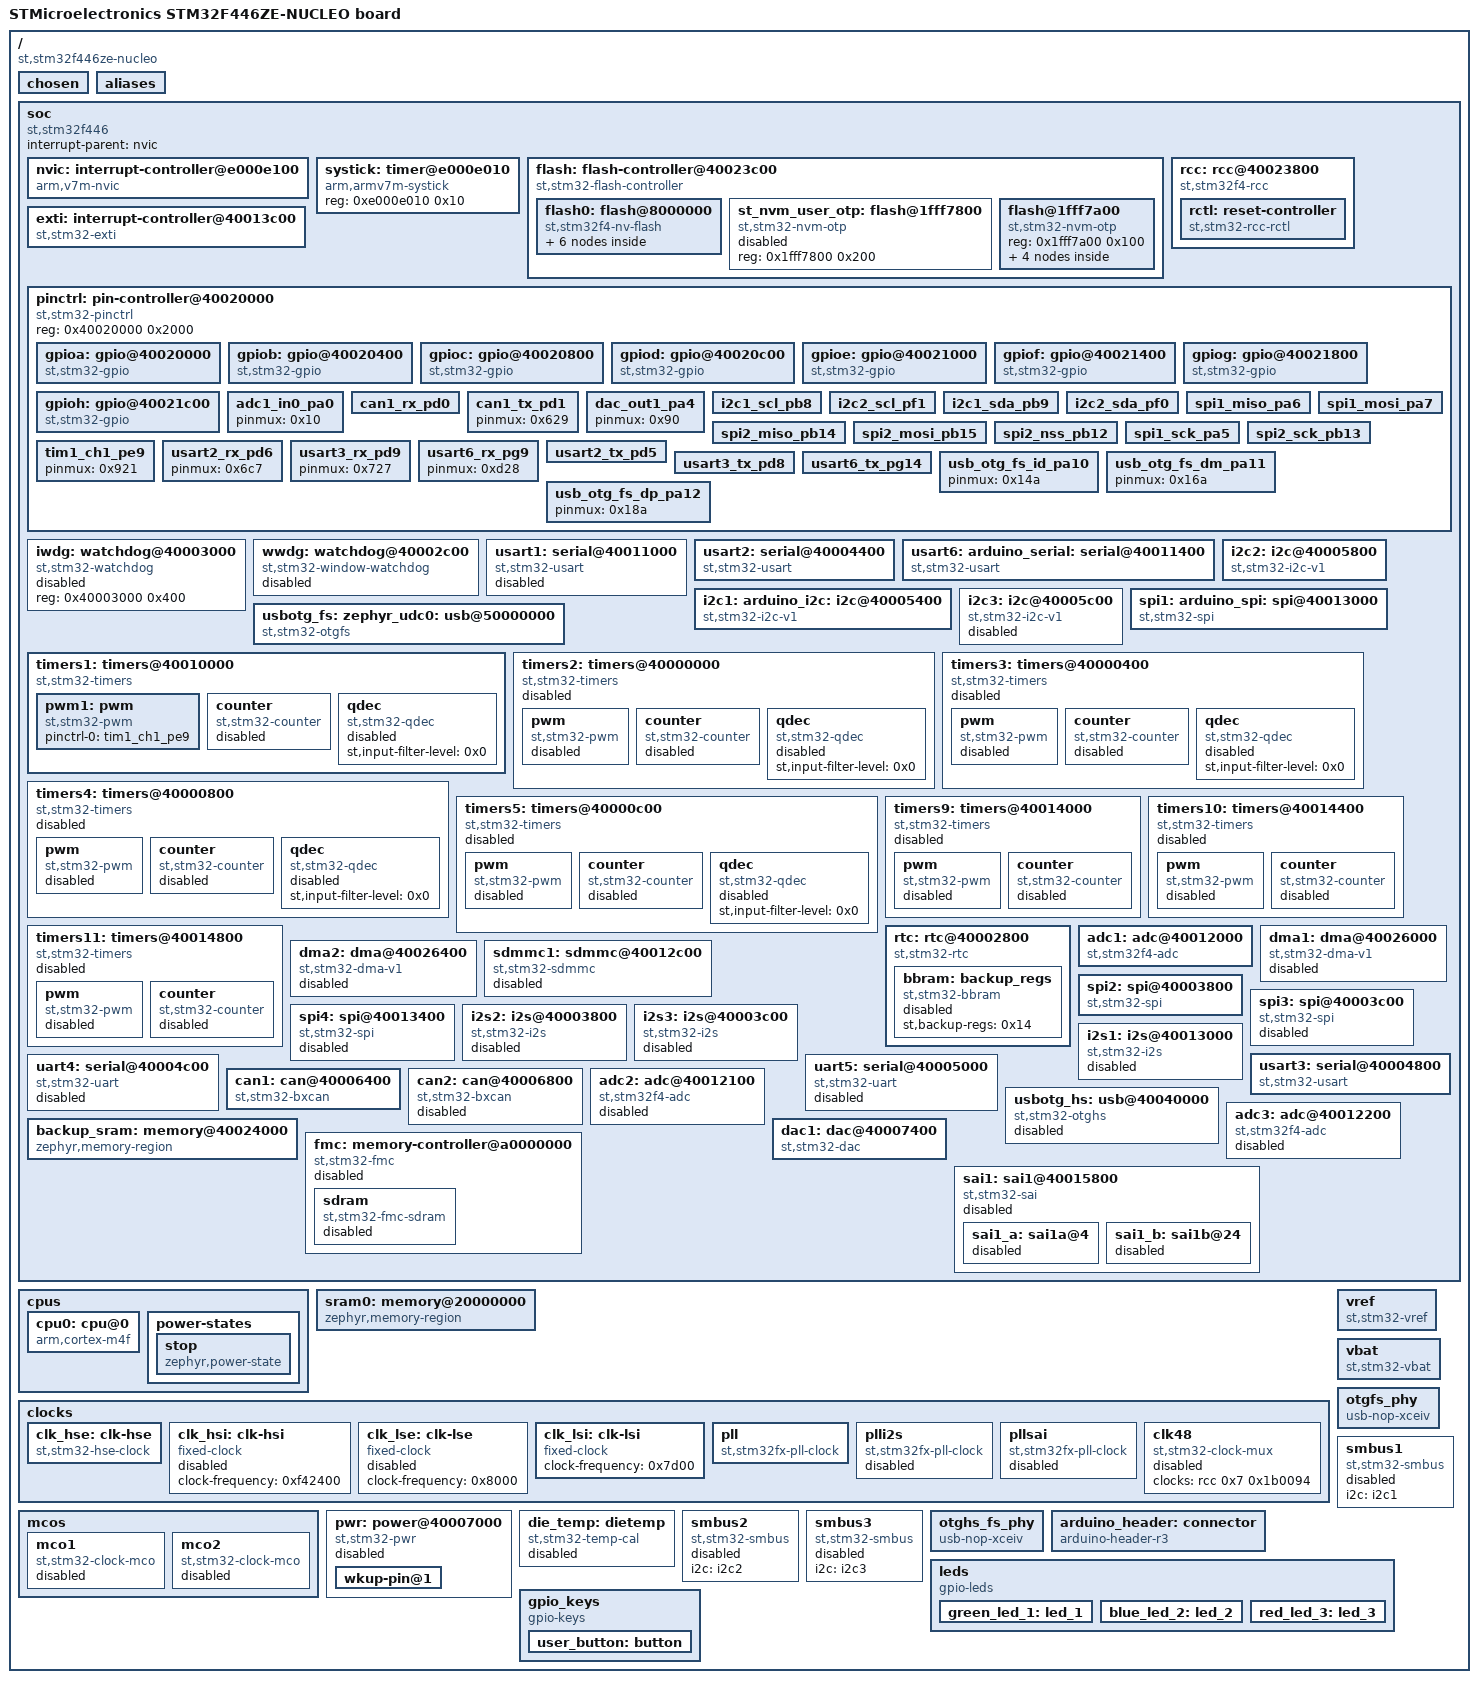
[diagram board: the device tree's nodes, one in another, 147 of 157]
/dts-v1/;

/* node '/' defined in zephyr/dts/common/skeleton.dtsi:9 */
/ {
	#address-cells = < 0x1 >;                              /* in zephyr/dts/common/skeleton.dtsi:10 */
	#size-cells = < 0x1 >;                                 /* in zephyr/dts/common/skeleton.dtsi:11 */
	model = "STMicroelectronics STM32F446ZE-NUCLEO board"; /* in zephyr/boards/st/nucleo_f446ze/nucleo_f446ze.dts:14 */
	compatible = "st,stm32f446ze-nucleo";                  /* in zephyr/boards/st/nucleo_f446ze/nucleo_f446ze.dts:15 */

	/* node '/chosen' defined in zephyr/dts/common/skeleton.dtsi:13 */
	chosen {
		zephyr,flash-controller = &flash;     /* in zephyr/dts/arm/st/f4/stm32f4.dtsi:26 */
		zephyr,system-timer-companion = &rtc; /* in zephyr/dts/arm/st/f4/stm32f4.dtsi:27 */
		zephyr,console = &usart3;             /* in zephyr/boards/st/nucleo_f446ze/nucleo_f446ze.dts:18 */
		zephyr,shell-uart = &usart3;          /* in zephyr/boards/st/nucleo_f446ze/nucleo_f446ze.dts:19 */
		zephyr,sram = &sram0;                 /* in zephyr/boards/st/nucleo_f446ze/nucleo_f446ze.dts:20 */
		zephyr,flash = &flash0;               /* in zephyr/boards/st/nucleo_f446ze/nucleo_f446ze.dts:21 */
		zephyr,canbus = &can1;                /* in zephyr/boards/st/nucleo_f446ze/nucleo_f446ze.dts:22 */
	};

	/* node '/aliases' defined in zephyr/dts/common/skeleton.dtsi:15 */
	aliases {
		led0 = &green_led_1;  /* in zephyr/boards/st/nucleo_f446ze/nucleo_f446ze.dts:55 */
		led1 = &blue_led_2;   /* in zephyr/boards/st/nucleo_f446ze/nucleo_f446ze.dts:56 */
		led2 = &red_led_3;    /* in zephyr/boards/st/nucleo_f446ze/nucleo_f446ze.dts:57 */
		sw0 = &user_button;   /* in zephyr/boards/st/nucleo_f446ze/nucleo_f446ze.dts:58 */
		volt-sensor0 = &vref; /* in zephyr/boards/st/nucleo_f446ze/nucleo_f446ze.dts:59 */
		volt-sensor1 = &vbat; /* in zephyr/boards/st/nucleo_f446ze/nucleo_f446ze.dts:60 */
	};

	/* node '/soc' defined in zephyr/dts/arm/armv7-m.dtsi:6 */
	soc {
		#address-cells = < 0x1 >;     /* in zephyr/dts/arm/armv7-m.dtsi:7 */
		#size-cells = < 0x1 >;        /* in zephyr/dts/arm/armv7-m.dtsi:8 */
		interrupt-parent = < &nvic >; /* in zephyr/dts/arm/armv7-m.dtsi:10 */
		ranges;                       /* in zephyr/dts/arm/armv7-m.dtsi:11 */
		compatible = "st,stm32f446",
		             "st,stm32f4",
		             "simple-bus";    /* in zephyr/dts/arm/st/f4/stm32f446.dtsi:29 */

		/* node '/soc/interrupt-controller@e000e100' defined in zephyr/dts/arm/armv7-m.dtsi:13 */
		nvic: interrupt-controller@e000e100 {
			#address-cells = < 0x1 >;            /* in zephyr/dts/arm/armv7-m.dtsi:14 */
			compatible = "arm,v7m-nvic";         /* in zephyr/dts/arm/armv7-m.dtsi:15 */
			reg = < 0xe000e100 0xc00 >;          /* in zephyr/dts/arm/armv7-m.dtsi:16 */
			interrupt-controller;                /* in zephyr/dts/arm/armv7-m.dtsi:17 */
			#interrupt-cells = < 0x2 >;          /* in zephyr/dts/arm/armv7-m.dtsi:18 */
			arm,num-irq-priority-bits = < 0x4 >; /* in zephyr/dts/arm/st/f4/stm32f4.dtsi:729 */
			phandle = < 0x1 >;                   /* in zephyr/dts/arm/armv7-m.dtsi:10 */
		};

		/* node '/soc/timer@e000e010' defined in zephyr/dts/arm/armv7-m.dtsi:21 */
		systick: timer@e000e010 {
			compatible = "arm,armv7m-systick"; /* in zephyr/dts/arm/armv7-m.dtsi:22 */
			reg = < 0xe000e010 0x10 >;         /* in zephyr/dts/arm/armv7-m.dtsi:23 */
		};

		/* node '/soc/flash-controller@40023c00' defined in zephyr/dts/arm/st/f4/stm32f4.dtsi:112 */
		flash: flash-controller@40023c00 {
			compatible = "st,stm32-flash-controller",
			             "st,stm32f4-flash-controller"; /* in zephyr/dts/arm/st/f4/stm32f4.dtsi:113 */
			reg = < 0x40023c00 0x400 >;                 /* in zephyr/dts/arm/st/f4/stm32f4.dtsi:114 */
			interrupts = < 0x4 0x0 >;                   /* in zephyr/dts/arm/st/f4/stm32f4.dtsi:115 */
			#address-cells = < 0x1 >;                   /* in zephyr/dts/arm/st/f4/stm32f4.dtsi:117 */
			#size-cells = < 0x1 >;                      /* in zephyr/dts/arm/st/f4/stm32f4.dtsi:118 */
			ranges;                                     /* in zephyr/dts/arm/st/f4/stm32f4.dtsi:119 */

			/* node '/soc/flash-controller@40023c00/flash@8000000' defined in zephyr/dts/arm/st/f4/stm32f4.dtsi:121 */
			flash0: flash@8000000 {
				compatible = "st,stm32f4-nv-flash",
				             "st,stm32-nv-flash",
				             "soc-nv-flash";        /* in zephyr/dts/arm/st/f4/stm32f4.dtsi:122 */
				#address-cells = < 0x1 >;           /* in zephyr/dts/arm/st/f4/stm32f4.dtsi:124 */
				#size-cells = < 0x1 >;              /* in zephyr/dts/arm/st/f4/stm32f4.dtsi:125 */
				write-block-size = < 0x1 >;         /* in zephyr/dts/arm/st/f4/stm32f4.dtsi:126 */
				max-erase-time = < 0xfa0 >;         /* in zephyr/dts/arm/st/f4/stm32f4.dtsi:128 */
				reg = < 0x8000000 0x80000 >;        /* in zephyr/dts/arm/st/f4/stm32f446Xe.dtsi:17 */
				ranges = < 0x0 0x8000000 0x80000 >; /* in zephyr/dts/arm/st/f4/stm32f446Xe.dtsi:18 */

				/* node '/soc/flash-controller@40023c00/flash@8000000/partitions' defined in zephyr/boards/st/nucleo_f446ze/nucleo_f446ze.dts:188 */
				partitions {
					#address-cells = < 0x1 >; /* in zephyr/boards/st/nucleo_f446ze/nucleo_f446ze.dts:189 */
					#size-cells = < 0x1 >;    /* in zephyr/boards/st/nucleo_f446ze/nucleo_f446ze.dts:190 */
					ranges;                   /* in zephyr/boards/st/nucleo_f446ze/nucleo_f446ze.dts:191 */

					/* node '/soc/flash-controller@40023c00/flash@8000000/partitions/partition@0' defined in zephyr/boards/st/nucleo_f446ze/nucleo_f446ze.dts:193 */
					boot_partition: partition@0 {
						compatible = "zephyr,mapped-partition"; /* in zephyr/boards/st/nucleo_f446ze/nucleo_f446ze.dts:194 */
						label = "mcuboot";                      /* in zephyr/boards/st/nucleo_f446ze/nucleo_f446ze.dts:195 */
						reg = < 0x0 0x10000 >;                  /* in zephyr/boards/st/nucleo_f446ze/nucleo_f446ze.dts:196 */
						read-only;                              /* in zephyr/boards/st/nucleo_f446ze/nucleo_f446ze.dts:197 */
					};

					/* node '/soc/flash-controller@40023c00/flash@8000000/partitions/partition@10000' defined in zephyr/boards/st/nucleo_f446ze/nucleo_f446ze.dts:205 */
					storage_partition: partition@10000 {
						compatible = "zephyr,mapped-partition"; /* in zephyr/boards/st/nucleo_f446ze/nucleo_f446ze.dts:206 */
						label = "storage";                      /* in zephyr/boards/st/nucleo_f446ze/nucleo_f446ze.dts:207 */
						reg = < 0x10000 0x10000 >;              /* in zephyr/boards/st/nucleo_f446ze/nucleo_f446ze.dts:208 */
					};

					/* node '/soc/flash-controller@40023c00/flash@8000000/partitions/partition@20000' defined in zephyr/boards/st/nucleo_f446ze/nucleo_f446ze.dts:211 */
					slot0_partition: partition@20000 {
						compatible = "zephyr,mapped-partition"; /* in zephyr/boards/st/nucleo_f446ze/nucleo_f446ze.dts:212 */
						label = "image-0";                      /* in zephyr/boards/st/nucleo_f446ze/nucleo_f446ze.dts:213 */
						reg = < 0x20000 0x20000 >;              /* in zephyr/boards/st/nucleo_f446ze/nucleo_f446ze.dts:214 */
					};

					/* node '/soc/flash-controller@40023c00/flash@8000000/partitions/partition@40000' defined in zephyr/boards/st/nucleo_f446ze/nucleo_f446ze.dts:217 */
					slot1_partition: partition@40000 {
						compatible = "zephyr,mapped-partition"; /* in zephyr/boards/st/nucleo_f446ze/nucleo_f446ze.dts:218 */
						label = "image-1";                      /* in zephyr/boards/st/nucleo_f446ze/nucleo_f446ze.dts:219 */
						reg = < 0x40000 0x20000 >;              /* in zephyr/boards/st/nucleo_f446ze/nucleo_f446ze.dts:220 */
					};

					/* node '/soc/flash-controller@40023c00/flash@8000000/partitions/partition@60000' defined in zephyr/boards/st/nucleo_f446ze/nucleo_f446ze.dts:223 */
					scratch_partition: partition@60000 {
						compatible = "zephyr,mapped-partition"; /* in zephyr/boards/st/nucleo_f446ze/nucleo_f446ze.dts:224 */
						label = "image-scratch";                /* in zephyr/boards/st/nucleo_f446ze/nucleo_f446ze.dts:225 */
						reg = < 0x60000 0x20000 >;              /* in zephyr/boards/st/nucleo_f446ze/nucleo_f446ze.dts:226 */
					};
				};
			};

			/* node '/soc/flash-controller@40023c00/flash@1fff7800' defined in zephyr/dts/arm/st/f4/stm32f4.dtsi:131 */
			st_nvm_user_otp: flash@1fff7800 {
				compatible = "st,stm32-nvm-otp"; /* in zephyr/dts/arm/st/f4/stm32f4.dtsi:132 */
				reg = < 0x1fff7800 0x200 >;      /* in zephyr/dts/arm/st/f4/stm32f4.dtsi:133 */
				status = "disabled";             /* in zephyr/dts/arm/st/f4/stm32f4.dtsi:134 */
			};

			/* node '/soc/flash-controller@40023c00/flash@1fff7a00' defined in zephyr/dts/arm/st/f4/stm32f4.dtsi:148 */
			flash@1fff7a00 {
				compatible = "st,stm32-nvm-otp"; /* in zephyr/dts/arm/st/f4/stm32f4.dtsi:149 */
				reg = < 0x1fff7a00 0x100 >;      /* in zephyr/dts/arm/st/f4/stm32f4.dtsi:150 */

				/* node '/soc/flash-controller@40023c00/flash@1fff7a00/nvmem-layout' defined in zephyr/dts/arm/st/f4/stm32f4.dtsi:152 */
				nvmem-layout {
					compatible = "fixed-layout"; /* in zephyr/dts/arm/st/f4/stm32f4.dtsi:153 */
					#address-cells = < 0x1 >;    /* in zephyr/dts/arm/st/f4/stm32f4.dtsi:154 */
					#size-cells = < 0x1 >;       /* in zephyr/dts/arm/st/f4/stm32f4.dtsi:155 */

					/* node '/soc/flash-controller@40023c00/flash@1fff7a00/nvmem-layout/vrefint@2a' defined in zephyr/dts/arm/st/f4/stm32f4.dtsi:157 */
					vrefint_otp: vrefint@2a {
						reg = < 0x2a 0x2 >;          /* in zephyr/dts/arm/st/f4/stm32f4.dtsi:158 */
						#nvmem-cell-cells = < 0x0 >; /* in zephyr/dts/arm/st/f4/stm32f4.dtsi:159 */
						read-only;                   /* in zephyr/dts/arm/st/f4/stm32f4.dtsi:160 */
						phandle = < 0x29 >;          /* in zephyr/dts/arm/st/f4/stm32f4.dtsi:685 */
					};

					/* node '/soc/flash-controller@40023c00/flash@1fff7a00/nvmem-layout/ts-cal1@2c' defined in zephyr/dts/arm/st/f4/stm32f4.dtsi:163 */
					ts_cal1_otp: ts-cal1@2c {
						reg = < 0x2c 0x2 >;          /* in zephyr/dts/arm/st/f4/stm32f4.dtsi:164 */
						#nvmem-cell-cells = < 0x0 >; /* in zephyr/dts/arm/st/f4/stm32f4.dtsi:165 */
						read-only;                   /* in zephyr/dts/arm/st/f4/stm32f4.dtsi:166 */
						phandle = < 0x26 >;          /* in zephyr/dts/arm/st/f4/stm32f4.dtsi:674 */
					};

					/* node '/soc/flash-controller@40023c00/flash@1fff7a00/nvmem-layout/ts-cal2@2e' defined in zephyr/dts/arm/st/f4/stm32f4.dtsi:169 */
					ts_cal2_otp: ts-cal2@2e {
						reg = < 0x2e 0x2 >;          /* in zephyr/dts/arm/st/f4/stm32f4.dtsi:170 */
						#nvmem-cell-cells = < 0x0 >; /* in zephyr/dts/arm/st/f4/stm32f4.dtsi:171 */
						read-only;                   /* in zephyr/dts/arm/st/f4/stm32f4.dtsi:172 */
						phandle = < 0x27 >;          /* in zephyr/dts/arm/st/f4/stm32f4.dtsi:674 */
					};
				};
			};
		};

		/* node '/soc/rcc@40023800' defined in zephyr/dts/arm/st/f4/stm32f4.dtsi:178 */
		rcc: rcc@40023800 {
			compatible = "st,stm32f4-rcc";   /* in zephyr/dts/arm/st/f4/stm32f4.dtsi:179 */
			#clock-cells = < 0x2 >;          /* in zephyr/dts/arm/st/f4/stm32f4.dtsi:180 */
			reg = < 0x40023800 0x400 >;      /* in zephyr/dts/arm/st/f4/stm32f4.dtsi:181 */
			clocks = < &pll >;               /* in zephyr/boards/st/nucleo_f446ze/nucleo_f446ze.dts:84 */
			clock-frequency = < 0xa037a00 >; /* in zephyr/boards/st/nucleo_f446ze/nucleo_f446ze.dts:85 */
			ahb-prescaler = < 0x1 >;         /* in zephyr/boards/st/nucleo_f446ze/nucleo_f446ze.dts:86 */
			apb1-prescaler = < 0x4 >;        /* in zephyr/boards/st/nucleo_f446ze/nucleo_f446ze.dts:87 */
			apb2-prescaler = < 0x2 >;        /* in zephyr/boards/st/nucleo_f446ze/nucleo_f446ze.dts:88 */
			phandle = < 0x3 >;               /* in zephyr/dts/arm/st/f4/stm32f4.dtsi:195 */

			/* node '/soc/rcc@40023800/reset-controller' defined in zephyr/dts/arm/st/f4/stm32f4.dtsi:183 */
			rctl: reset-controller {
				compatible = "st,stm32-rcc-rctl"; /* in zephyr/dts/arm/st/f4/stm32f4.dtsi:184 */
				#reset-cells = < 0x1 >;           /* in zephyr/dts/arm/st/f4/stm32f4.dtsi:185 */
				phandle = < 0x4 >;                /* in zephyr/dts/arm/st/f4/stm32f4.dtsi:294 */
			};
		};

		/* node '/soc/interrupt-controller@40013c00' defined in zephyr/dts/arm/st/f4/stm32f4.dtsi:189 */
		exti: interrupt-controller@40013c00 {
			compatible = "st,stm32-exti";  /* in zephyr/dts/arm/st/f4/stm32f4.dtsi:190 */
			interrupt-controller;          /* in zephyr/dts/arm/st/f4/stm32f4.dtsi:191 */
			#interrupt-cells = < 0x1 >;    /* in zephyr/dts/arm/st/f4/stm32f4.dtsi:192 */
			#address-cells = < 0x0 >;      /* in zephyr/dts/arm/st/f4/stm32f4.dtsi:193 */
			reg = < 0x40013c00 0x400 >;    /* in zephyr/dts/arm/st/f4/stm32f4.dtsi:194 */
			clocks = < &rcc 0x44 0x4000 >; /* in zephyr/dts/arm/st/f4/stm32f4.dtsi:195 */
			num-lines = < 0x20 >;          /* in zephyr/dts/arm/st/f4/stm32f4.dtsi:196 */
			interrupts = < 0x6 0x0 >,
			             < 0x7 0x0 >,
			             < 0x8 0x0 >,
			             < 0x9 0x0 >,
			             < 0xa 0x0 >,
			             < 0x17 0x0 >,
			             < 0x28 0x0 >;     /* in zephyr/dts/arm/st/f4/stm32f4.dtsi:197 */
			interrupt-names = "line0",
			                  "line1",
			                  "line2",
			                  "line3",
			                  "line4",
			                  "line5-9",
			                  "line10-15"; /* in zephyr/dts/arm/st/f4/stm32f4.dtsi:199 */
			line-ranges = < 0x0 0x1 >,
			              < 0x1 0x1 >,
			              < 0x2 0x1 >,
			              < 0x3 0x1 >,
			              < 0x4 0x1 >,
			              < 0x5 0x5 >,
			              < 0xa 0x6 >;     /* in zephyr/dts/arm/st/f4/stm32f4.dtsi:201 */
		};

		/* node '/soc/pin-controller@40020000' defined in zephyr/dts/arm/st/f4/stm32f4.dtsi:205 */
		pinctrl: pin-controller@40020000 {
			compatible = "st,stm32-pinctrl"; /* in zephyr/dts/arm/st/f4/stm32f4.dtsi:206 */
			#address-cells = < 0x1 >;        /* in zephyr/dts/arm/st/f4/stm32f4.dtsi:207 */
			#size-cells = < 0x1 >;           /* in zephyr/dts/arm/st/f4/stm32f4.dtsi:208 */
			reg = < 0x40020000 0x2000 >;     /* in zephyr/dts/arm/st/f4/stm32f4.dtsi:209 */

			/* node '/soc/pin-controller@40020000/gpio@40020000' defined in zephyr/dts/arm/st/f4/stm32f4.dtsi:211 */
			gpioa: gpio@40020000 {
				compatible = "st,stm32-gpio"; /* in zephyr/dts/arm/st/f4/stm32f4.dtsi:212 */
				gpio-controller;              /* in zephyr/dts/arm/st/f4/stm32f4.dtsi:213 */
				#gpio-cells = < 0x2 >;        /* in zephyr/dts/arm/st/f4/stm32f4.dtsi:214 */
				reg = < 0x40020000 0x400 >;   /* in zephyr/dts/arm/st/f4/stm32f4.dtsi:215 */
				clocks = < &rcc 0x30 0x1 >;   /* in zephyr/dts/arm/st/f4/stm32f4.dtsi:216 */
				phandle = < 0x25 >;           /* in zephyr/dts/arm/st/f4/stm32f4.dtsi:668 */
			};

			/* node '/soc/pin-controller@40020000/gpio@40020400' defined in zephyr/dts/arm/st/f4/stm32f4.dtsi:219 */
			gpiob: gpio@40020400 {
				compatible = "st,stm32-gpio"; /* in zephyr/dts/arm/st/f4/stm32f4.dtsi:220 */
				gpio-controller;              /* in zephyr/dts/arm/st/f4/stm32f4.dtsi:221 */
				#gpio-cells = < 0x2 >;        /* in zephyr/dts/arm/st/f4/stm32f4.dtsi:222 */
				reg = < 0x40020400 0x400 >;   /* in zephyr/dts/arm/st/f4/stm32f4.dtsi:223 */
				clocks = < &rcc 0x30 0x2 >;   /* in zephyr/dts/arm/st/f4/stm32f4.dtsi:224 */
				phandle = < 0x31 >;           /* in zephyr/boards/st/nucleo_f446ze/arduino_r3_connector.dtsi:15 */
			};

			/* node '/soc/pin-controller@40020000/gpio@40020800' defined in zephyr/dts/arm/st/f4/stm32f4.dtsi:227 */
			gpioc: gpio@40020800 {
				compatible = "st,stm32-gpio"; /* in zephyr/dts/arm/st/f4/stm32f4.dtsi:228 */
				gpio-controller;              /* in zephyr/dts/arm/st/f4/stm32f4.dtsi:229 */
				#gpio-cells = < 0x2 >;        /* in zephyr/dts/arm/st/f4/stm32f4.dtsi:230 */
				reg = < 0x40020800 0x400 >;   /* in zephyr/dts/arm/st/f4/stm32f4.dtsi:231 */
				clocks = < &rcc 0x30 0x4 >;   /* in zephyr/dts/arm/st/f4/stm32f4.dtsi:232 */
				phandle = < 0x2d >;           /* in zephyr/boards/st/nucleo_f446ze/arduino_r3_connector.dtsi:15 */
			};

			/* node '/soc/pin-controller@40020000/gpio@40020c00' defined in zephyr/dts/arm/st/f4/stm32f4.dtsi:235 */
			gpiod: gpio@40020c00 {
				compatible = "st,stm32-gpio"; /* in zephyr/dts/arm/st/f4/stm32f4.dtsi:236 */
				gpio-controller;              /* in zephyr/dts/arm/st/f4/stm32f4.dtsi:237 */
				#gpio-cells = < 0x2 >;        /* in zephyr/dts/arm/st/f4/stm32f4.dtsi:238 */
				reg = < 0x40020c00 0x400 >;   /* in zephyr/dts/arm/st/f4/stm32f4.dtsi:239 */
				clocks = < &rcc 0x30 0x8 >;   /* in zephyr/dts/arm/st/f4/stm32f4.dtsi:240 */
				phandle = < 0x10 >;           /* in zephyr/boards/st/nucleo_f446ze/nucleo_f446ze.dts:143 */
			};

			/* node '/soc/pin-controller@40020000/gpio@40021000' defined in zephyr/dts/arm/st/f4/stm32f4.dtsi:243 */
			gpioe: gpio@40021000 {
				compatible = "st,stm32-gpio"; /* in zephyr/dts/arm/st/f4/stm32f4.dtsi:244 */
				gpio-controller;              /* in zephyr/dts/arm/st/f4/stm32f4.dtsi:245 */
				#gpio-cells = < 0x2 >;        /* in zephyr/dts/arm/st/f4/stm32f4.dtsi:246 */
				reg = < 0x40021000 0x400 >;   /* in zephyr/dts/arm/st/f4/stm32f4.dtsi:247 */
				clocks = < &rcc 0x30 0x10 >;  /* in zephyr/dts/arm/st/f4/stm32f4.dtsi:248 */
				phandle = < 0x30 >;           /* in zephyr/boards/st/nucleo_f446ze/arduino_r3_connector.dtsi:15 */
			};

			/* node '/soc/pin-controller@40020000/gpio@40021400' defined in zephyr/dts/arm/st/f4/stm32f4.dtsi:251 */
			gpiof: gpio@40021400 {
				compatible = "st,stm32-gpio"; /* in zephyr/dts/arm/st/f4/stm32f4.dtsi:252 */
				gpio-controller;              /* in zephyr/dts/arm/st/f4/stm32f4.dtsi:253 */
				#gpio-cells = < 0x2 >;        /* in zephyr/dts/arm/st/f4/stm32f4.dtsi:254 */
				reg = < 0x40021400 0x400 >;   /* in zephyr/dts/arm/st/f4/stm32f4.dtsi:255 */
				clocks = < &rcc 0x30 0x20 >;  /* in zephyr/dts/arm/st/f4/stm32f4.dtsi:256 */
				phandle = < 0x2e >;           /* in zephyr/boards/st/nucleo_f446ze/arduino_r3_connector.dtsi:15 */
			};

			/* node '/soc/pin-controller@40020000/gpio@40021800' defined in zephyr/dts/arm/st/f4/stm32f4.dtsi:259 */
			gpiog: gpio@40021800 {
				compatible = "st,stm32-gpio"; /* in zephyr/dts/arm/st/f4/stm32f4.dtsi:260 */
				gpio-controller;              /* in zephyr/dts/arm/st/f4/stm32f4.dtsi:261 */
				#gpio-cells = < 0x2 >;        /* in zephyr/dts/arm/st/f4/stm32f4.dtsi:262 */
				reg = < 0x40021800 0x400 >;   /* in zephyr/dts/arm/st/f4/stm32f4.dtsi:263 */
				clocks = < &rcc 0x30 0x40 >;  /* in zephyr/dts/arm/st/f4/stm32f4.dtsi:264 */
				phandle = < 0x2f >;           /* in zephyr/boards/st/nucleo_f446ze/arduino_r3_connector.dtsi:15 */
			};

			/* node '/soc/pin-controller@40020000/gpio@40021c00' defined in zephyr/dts/arm/st/f4/stm32f4.dtsi:267 */
			gpioh: gpio@40021c00 {
				compatible = "st,stm32-gpio"; /* in zephyr/dts/arm/st/f4/stm32f4.dtsi:268 */
				gpio-controller;              /* in zephyr/dts/arm/st/f4/stm32f4.dtsi:269 */
				#gpio-cells = < 0x2 >;        /* in zephyr/dts/arm/st/f4/stm32f4.dtsi:270 */
				reg = < 0x40021c00 0x400 >;   /* in zephyr/dts/arm/st/f4/stm32f4.dtsi:271 */
				clocks = < &rcc 0x30 0x80 >;  /* in zephyr/dts/arm/st/f4/stm32f4.dtsi:272 */
			};

			/* node '/soc/pin-controller@40020000/adc1_in0_pa0' defined in modules/hal/stm32/dts/st/f4/stm32f446z(c-e)tx-pinctrl.dtsi:13 */
			adc1_in0_pa0: adc1_in0_pa0 {
				pinmux = < 0x10 >;  /* in modules/hal/stm32/dts/st/f4/stm32f446z(c-e)tx-pinctrl.dtsi:14 */
				phandle = < 0x16 >; /* in zephyr/boards/st/nucleo_f446ze/nucleo_f446ze.dts:92 */
			};

			/* node '/soc/pin-controller@40020000/can1_rx_pd0' defined in modules/hal/stm32/dts/st/f4/stm32f446z(c-e)tx-pinctrl.dtsi:675 */
			can1_rx_pd0: can1_rx_pd0 {
				pinmux = < 0x609 >; /* in modules/hal/stm32/dts/st/f4/stm32f446z(c-e)tx-pinctrl.dtsi:676 */
				bias-pull-up;       /* in modules/hal/stm32/dts/st/f4/stm32f446z(c-e)tx-pinctrl.dtsi:677 */
				phandle = < 0x1f >; /* in zephyr/boards/st/nucleo_f446ze/nucleo_f446ze.dts:182 */
			};

			/* node '/soc/pin-controller@40020000/can1_tx_pd1' defined in modules/hal/stm32/dts/st/f4/stm32f446z(c-e)tx-pinctrl.dtsi:700 */
			can1_tx_pd1: can1_tx_pd1 {
				pinmux = < 0x629 >; /* in modules/hal/stm32/dts/st/f4/stm32f446z(c-e)tx-pinctrl.dtsi:701 */
				phandle = < 0x20 >; /* in zephyr/boards/st/nucleo_f446ze/nucleo_f446ze.dts:182 */
			};

			/* node '/soc/pin-controller@40020000/dac_out1_pa4' defined in modules/hal/stm32/dts/st/f4/stm32f446z(c-e)tx-pinctrl.dtsi:714 */
			dac_out1_pa4: dac_out1_pa4 {
				pinmux = < 0x90 >;  /* in modules/hal/stm32/dts/st/f4/stm32f446z(c-e)tx-pinctrl.dtsi:715 */
				phandle = < 0x22 >; /* in zephyr/boards/st/nucleo_f446ze/nucleo_f446ze.dts:101 */
			};

			/* node '/soc/pin-controller@40020000/i2c1_scl_pb8' defined in modules/hal/stm32/dts/st/f4/stm32f446z(c-e)tx-pinctrl.dtsi:1290 */
			i2c1_scl_pb8: i2c1_scl_pb8 {
				pinmux = < 0x304 >; /* in modules/hal/stm32/dts/st/f4/stm32f446z(c-e)tx-pinctrl.dtsi:1291 */
				bias-pull-up;       /* in modules/hal/stm32/dts/st/f4/stm32f446z(c-e)tx-pinctrl.dtsi:1292 */
				drive-open-drain;   /* in modules/hal/stm32/dts/st/f4/stm32f446z(c-e)tx-pinctrl.dtsi:1293 */
				phandle = < 0x9 >;  /* in zephyr/boards/st/nucleo_f446ze/nucleo_f446ze.dts:127 */
			};

			/* node '/soc/pin-controller@40020000/i2c2_scl_pf1' defined in modules/hal/stm32/dts/st/f4/stm32f446z(c-e)tx-pinctrl.dtsi:1302 */
			i2c2_scl_pf1: i2c2_scl_pf1 {
				pinmux = < 0xa24 >; /* in modules/hal/stm32/dts/st/f4/stm32f446z(c-e)tx-pinctrl.dtsi:1303 */
				bias-pull-up;       /* in modules/hal/stm32/dts/st/f4/stm32f446z(c-e)tx-pinctrl.dtsi:1304 */
				drive-open-drain;   /* in modules/hal/stm32/dts/st/f4/stm32f446z(c-e)tx-pinctrl.dtsi:1305 */
				phandle = < 0xb >;  /* in zephyr/boards/st/nucleo_f446ze/nucleo_f446ze.dts:134 */
			};

			/* node '/soc/pin-controller@40020000/i2c1_sda_pb9' defined in modules/hal/stm32/dts/st/f4/stm32f446z(c-e)tx-pinctrl.dtsi:1322 */
			i2c1_sda_pb9: i2c1_sda_pb9 {
				pinmux = < 0x324 >; /* in modules/hal/stm32/dts/st/f4/stm32f446z(c-e)tx-pinctrl.dtsi:1323 */
				bias-pull-up;       /* in modules/hal/stm32/dts/st/f4/stm32f446z(c-e)tx-pinctrl.dtsi:1324 */
				drive-open-drain;   /* in modules/hal/stm32/dts/st/f4/stm32f446z(c-e)tx-pinctrl.dtsi:1325 */
				phandle = < 0xa >;  /* in zephyr/boards/st/nucleo_f446ze/nucleo_f446ze.dts:127 */
			};

			/* node '/soc/pin-controller@40020000/i2c2_sda_pf0' defined in modules/hal/stm32/dts/st/f4/stm32f446z(c-e)tx-pinctrl.dtsi:1346 */
			i2c2_sda_pf0: i2c2_sda_pf0 {
				pinmux = < 0xa04 >; /* in modules/hal/stm32/dts/st/f4/stm32f446z(c-e)tx-pinctrl.dtsi:1347 */
				bias-pull-up;       /* in modules/hal/stm32/dts/st/f4/stm32f446z(c-e)tx-pinctrl.dtsi:1348 */
				drive-open-drain;   /* in modules/hal/stm32/dts/st/f4/stm32f446z(c-e)tx-pinctrl.dtsi:1349 */
				phandle = < 0xc >;  /* in zephyr/boards/st/nucleo_f446ze/nucleo_f446ze.dts:134 */
			};

			/* node '/soc/pin-controller@40020000/spi1_miso_pa6' defined in modules/hal/stm32/dts/st/f4/stm32f446z(c-e)tx-pinctrl.dtsi:1941 */
			spi1_miso_pa6: spi1_miso_pa6 {
				pinmux = < 0xc5 >;             /* in modules/hal/stm32/dts/st/f4/stm32f446z(c-e)tx-pinctrl.dtsi:1942 */
				bias-pull-down;                /* in modules/hal/stm32/dts/st/f4/stm32f446z(c-e)tx-pinctrl.dtsi:1943 */
				slew-rate = "very-high-speed"; /* in modules/hal/stm32/dts/st/f4/stm32f446z(c-e)tx-pinctrl.dtsi:1944 */
				phandle = < 0xe >;             /* in zephyr/boards/st/nucleo_f446ze/nucleo_f446ze.dts:141 */
			};

			/* node '/soc/pin-controller@40020000/spi2_miso_pb14' defined in modules/hal/stm32/dts/st/f4/stm32f446z(c-e)tx-pinctrl.dtsi:1953 */
			spi2_miso_pb14: spi2_miso_pb14 {
				pinmux = < 0x3c5 >;            /* in modules/hal/stm32/dts/st/f4/stm32f446z(c-e)tx-pinctrl.dtsi:1954 */
				bias-pull-down;                /* in modules/hal/stm32/dts/st/f4/stm32f446z(c-e)tx-pinctrl.dtsi:1955 */
				slew-rate = "very-high-speed"; /* in modules/hal/stm32/dts/st/f4/stm32f446z(c-e)tx-pinctrl.dtsi:1956 */
				phandle = < 0x19 >;            /* in zephyr/boards/st/nucleo_f446ze/nucleo_f446ze.dts:148 */
			};

			/* node '/soc/pin-controller@40020000/spi1_mosi_pa7' defined in modules/hal/stm32/dts/st/f4/stm32f446z(c-e)tx-pinctrl.dtsi:2003 */
			spi1_mosi_pa7: spi1_mosi_pa7 {
				pinmux = < 0xe5 >;             /* in modules/hal/stm32/dts/st/f4/stm32f446z(c-e)tx-pinctrl.dtsi:2004 */
				bias-pull-down;                /* in modules/hal/stm32/dts/st/f4/stm32f446z(c-e)tx-pinctrl.dtsi:2005 */
				slew-rate = "very-high-speed"; /* in modules/hal/stm32/dts/st/f4/stm32f446z(c-e)tx-pinctrl.dtsi:2006 */
				phandle = < 0xf >;             /* in zephyr/boards/st/nucleo_f446ze/nucleo_f446ze.dts:141 */
			};

			/* node '/soc/pin-controller@40020000/spi2_mosi_pb15' defined in modules/hal/stm32/dts/st/f4/stm32f446z(c-e)tx-pinctrl.dtsi:2015 */
			spi2_mosi_pb15: spi2_mosi_pb15 {
				pinmux = < 0x3e5 >;            /* in modules/hal/stm32/dts/st/f4/stm32f446z(c-e)tx-pinctrl.dtsi:2016 */
				bias-pull-down;                /* in modules/hal/stm32/dts/st/f4/stm32f446z(c-e)tx-pinctrl.dtsi:2017 */
				slew-rate = "very-high-speed"; /* in modules/hal/stm32/dts/st/f4/stm32f446z(c-e)tx-pinctrl.dtsi:2018 */
				phandle = < 0x1a >;            /* in zephyr/boards/st/nucleo_f446ze/nucleo_f446ze.dts:148 */
			};

			/* node '/soc/pin-controller@40020000/spi2_nss_pb12' defined in modules/hal/stm32/dts/st/f4/stm32f446z(c-e)tx-pinctrl.dtsi:2119 */
			spi2_nss_pb12: spi2_nss_pb12 {
				pinmux = < 0x385 >;            /* in modules/hal/stm32/dts/st/f4/stm32f446z(c-e)tx-pinctrl.dtsi:2120 */
				bias-pull-up;                  /* in modules/hal/stm32/dts/st/f4/stm32f446z(c-e)tx-pinctrl.dtsi:2121 */
				slew-rate = "very-high-speed"; /* in modules/hal/stm32/dts/st/f4/stm32f446z(c-e)tx-pinctrl.dtsi:2122 */
				phandle = < 0x17 >;            /* in zephyr/boards/st/nucleo_f446ze/nucleo_f446ze.dts:148 */
			};

			/* node '/soc/pin-controller@40020000/spi1_sck_pa5' defined in modules/hal/stm32/dts/st/f4/stm32f446z(c-e)tx-pinctrl.dtsi:2163 */
			spi1_sck_pa5: spi1_sck_pa5 {
				pinmux = < 0xa5 >;             /* in modules/hal/stm32/dts/st/f4/stm32f446z(c-e)tx-pinctrl.dtsi:2164 */
				bias-pull-down;                /* in modules/hal/stm32/dts/st/f4/stm32f446z(c-e)tx-pinctrl.dtsi:2165 */
				slew-rate = "very-high-speed"; /* in modules/hal/stm32/dts/st/f4/stm32f446z(c-e)tx-pinctrl.dtsi:2166 */
				phandle = < 0xd >;             /* in zephyr/boards/st/nucleo_f446ze/nucleo_f446ze.dts:141 */
			};

			/* node '/soc/pin-controller@40020000/spi2_sck_pb13' defined in modules/hal/stm32/dts/st/f4/stm32f446z(c-e)tx-pinctrl.dtsi:2187 */
			spi2_sck_pb13: spi2_sck_pb13 {
				pinmux = < 0x3a5 >;            /* in modules/hal/stm32/dts/st/f4/stm32f446z(c-e)tx-pinctrl.dtsi:2188 */
				bias-pull-down;                /* in modules/hal/stm32/dts/st/f4/stm32f446z(c-e)tx-pinctrl.dtsi:2189 */
				slew-rate = "very-high-speed"; /* in modules/hal/stm32/dts/st/f4/stm32f446z(c-e)tx-pinctrl.dtsi:2190 */
				phandle = < 0x18 >;            /* in zephyr/boards/st/nucleo_f446ze/nucleo_f446ze.dts:148 */
			};

			/* node '/soc/pin-controller@40020000/tim1_ch1_pe9' defined in modules/hal/stm32/dts/st/f4/stm32f446z(c-e)tx-pinctrl.dtsi:2311 */
			tim1_ch1_pe9: tim1_ch1_pe9 {
				pinmux = < 0x921 >; /* in modules/hal/stm32/dts/st/f4/stm32f446z(c-e)tx-pinctrl.dtsi:2312 */
				phandle = < 0x15 >; /* in zephyr/boards/st/nucleo_f446ze/nucleo_f446ze.dts:166 */
			};

			/* node '/soc/pin-controller@40020000/usart2_rx_pd6' defined in modules/hal/stm32/dts/st/f4/stm32f446z(c-e)tx-pinctrl.dtsi:2663 */
			usart2_rx_pd6: usart2_rx_pd6 {
				pinmux = < 0x6c7 >; /* in modules/hal/stm32/dts/st/f4/stm32f446z(c-e)tx-pinctrl.dtsi:2664 */
				phandle = < 0x6 >;  /* in zephyr/boards/st/nucleo_f446ze/nucleo_f446ze.dts:106 */
			};

			/* node '/soc/pin-controller@40020000/usart3_rx_pd9' defined in modules/hal/stm32/dts/st/f4/stm32f446z(c-e)tx-pinctrl.dtsi:2679 */
			usart3_rx_pd9: usart3_rx_pd9 {
				pinmux = < 0x727 >; /* in modules/hal/stm32/dts/st/f4/stm32f446z(c-e)tx-pinctrl.dtsi:2680 */
				phandle = < 0x1e >; /* in zephyr/boards/st/nucleo_f446ze/nucleo_f446ze.dts:113 */
			};

			/* node '/soc/pin-controller@40020000/usart6_rx_pg9' defined in modules/hal/stm32/dts/st/f4/stm32f446z(c-e)tx-pinctrl.dtsi:2703 */
			usart6_rx_pg9: usart6_rx_pg9 {
				pinmux = < 0xd28 >; /* in modules/hal/stm32/dts/st/f4/stm32f446z(c-e)tx-pinctrl.dtsi:2704 */
				phandle = < 0x8 >;  /* in zephyr/boards/st/nucleo_f446ze/nucleo_f446ze.dts:120 */
			};

			/* node '/soc/pin-controller@40020000/usart2_tx_pd5' defined in modules/hal/stm32/dts/st/f4/stm32f446z(c-e)tx-pinctrl.dtsi:2724 */
			usart2_tx_pd5: usart2_tx_pd5 {
				pinmux = < 0x6a7 >; /* in modules/hal/stm32/dts/st/f4/stm32f446z(c-e)tx-pinctrl.dtsi:2725 */
				bias-pull-up;       /* in modules/hal/stm32/dts/st/f4/stm32f446z(c-e)tx-pinctrl.dtsi:2726 */
				phandle = < 0x5 >;  /* in zephyr/boards/st/nucleo_f446ze/nucleo_f446ze.dts:106 */
			};

			/* node '/soc/pin-controller@40020000/usart3_tx_pd8' defined in modules/hal/stm32/dts/st/f4/stm32f446z(c-e)tx-pinctrl.dtsi:2739 */
			usart3_tx_pd8: usart3_tx_pd8 {
				pinmux = < 0x707 >; /* in modules/hal/stm32/dts/st/f4/stm32f446z(c-e)tx-pinctrl.dtsi:2740 */
				bias-pull-up;       /* in modules/hal/stm32/dts/st/f4/stm32f446z(c-e)tx-pinctrl.dtsi:2741 */
				phandle = < 0x1d >; /* in zephyr/boards/st/nucleo_f446ze/nucleo_f446ze.dts:113 */
			};

			/* node '/soc/pin-controller@40020000/usart6_tx_pg14' defined in modules/hal/stm32/dts/st/f4/stm32f446z(c-e)tx-pinctrl.dtsi:2769 */
			usart6_tx_pg14: usart6_tx_pg14 {
				pinmux = < 0xdc8 >; /* in modules/hal/stm32/dts/st/f4/stm32f446z(c-e)tx-pinctrl.dtsi:2770 */
				bias-pull-up;       /* in modules/hal/stm32/dts/st/f4/stm32f446z(c-e)tx-pinctrl.dtsi:2771 */
				phandle = < 0x7 >;  /* in zephyr/boards/st/nucleo_f446ze/nucleo_f446ze.dts:120 */
			};

			/* node '/soc/pin-controller@40020000/usb_otg_fs_id_pa10' defined in modules/hal/stm32/dts/st/f4/stm32f446z(c-e)tx-pinctrl.dtsi:2784 */
			usb_otg_fs_id_pa10: usb_otg_fs_id_pa10 {
				pinmux = < 0x14a >; /* in modules/hal/stm32/dts/st/f4/stm32f446z(c-e)tx-pinctrl.dtsi:2785 */
				phandle = < 0x14 >; /* in zephyr/boards/st/nucleo_f446ze/nucleo_f446ze.dts:155 */
			};

			/* node '/soc/pin-controller@40020000/usb_otg_fs_dm_pa11' defined in modules/hal/stm32/dts/st/f4/stm32f446z(c-e)tx-pinctrl.dtsi:2788 */
			usb_otg_fs_dm_pa11: usb_otg_fs_dm_pa11 {
				pinmux = < 0x16a >; /* in modules/hal/stm32/dts/st/f4/stm32f446z(c-e)tx-pinctrl.dtsi:2789 */
				phandle = < 0x12 >; /* in zephyr/boards/st/nucleo_f446ze/nucleo_f446ze.dts:155 */
			};

			/* node '/soc/pin-controller@40020000/usb_otg_fs_dp_pa12' defined in modules/hal/stm32/dts/st/f4/stm32f446z(c-e)tx-pinctrl.dtsi:2792 */
			usb_otg_fs_dp_pa12: usb_otg_fs_dp_pa12 {
				pinmux = < 0x18a >; /* in modules/hal/stm32/dts/st/f4/stm32f446z(c-e)tx-pinctrl.dtsi:2793 */
				phandle = < 0x13 >; /* in zephyr/boards/st/nucleo_f446ze/nucleo_f446ze.dts:155 */
			};
		};

		/* node '/soc/watchdog@40003000' defined in zephyr/dts/arm/st/f4/stm32f4.dtsi:276 */
		iwdg: watchdog@40003000 {
			compatible = "st,stm32-watchdog"; /* in zephyr/dts/arm/st/f4/stm32f4.dtsi:277 */
			reg = < 0x40003000 0x400 >;       /* in zephyr/dts/arm/st/f4/stm32f4.dtsi:278 */
			status = "disabled";              /* in zephyr/dts/arm/st/f4/stm32f4.dtsi:279 */
		};

		/* node '/soc/watchdog@40002c00' defined in zephyr/dts/arm/st/f4/stm32f4.dtsi:282 */
		wwdg: watchdog@40002c00 {
			compatible = "st,stm32-window-watchdog"; /* in zephyr/dts/arm/st/f4/stm32f4.dtsi:283 */
			reg = < 0x40002c00 0x400 >;              /* in zephyr/dts/arm/st/f4/stm32f4.dtsi:284 */
			clocks = < &rcc 0x40 0x800 >;            /* in zephyr/dts/arm/st/f4/stm32f4.dtsi:285 */
			interrupts = < 0x0 0x0 >;                /* in zephyr/dts/arm/st/f4/stm32f4.dtsi:286 */
			status = "disabled";                     /* in zephyr/dts/arm/st/f4/stm32f4.dtsi:287 */
		};

		/* node '/soc/serial@40011000' defined in zephyr/dts/arm/st/f4/stm32f4.dtsi:290 */
		usart1: serial@40011000 {
			compatible = "st,stm32-usart",
			             "st,stm32-uart";  /* in zephyr/dts/arm/st/f4/stm32f4.dtsi:291 */
			reg = < 0x40011000 0x400 >;    /* in zephyr/dts/arm/st/f4/stm32f4.dtsi:292 */
			clocks = < &rcc 0x44 0x10 >;   /* in zephyr/dts/arm/st/f4/stm32f4.dtsi:293 */
			resets = < &rctl 0x484 >;      /* in zephyr/dts/arm/st/f4/stm32f4.dtsi:294 */
			interrupts = < 0x25 0x0 >;     /* in zephyr/dts/arm/st/f4/stm32f4.dtsi:295 */
			status = "disabled";           /* in zephyr/dts/arm/st/f4/stm32f4.dtsi:296 */
		};

		/* node '/soc/serial@40004400' defined in zephyr/dts/arm/st/f4/stm32f4.dtsi:299 */
		usart2: serial@40004400 {
			compatible = "st,stm32-usart",
			             "st,stm32-uart";                  /* in zephyr/dts/arm/st/f4/stm32f4.dtsi:300 */
			reg = < 0x40004400 0x400 >;                    /* in zephyr/dts/arm/st/f4/stm32f4.dtsi:301 */
			clocks = < &rcc 0x40 0x20000 >;                /* in zephyr/dts/arm/st/f4/stm32f4.dtsi:302 */
			resets = < &rctl 0x411 >;                      /* in zephyr/dts/arm/st/f4/stm32f4.dtsi:303 */
			interrupts = < 0x26 0x0 >;                     /* in zephyr/dts/arm/st/f4/stm32f4.dtsi:304 */
			pinctrl-0 = < &usart2_tx_pd5 &usart2_rx_pd6 >; /* in zephyr/boards/st/nucleo_f446ze/nucleo_f446ze.dts:106 */
			pinctrl-names = "default";                     /* in zephyr/boards/st/nucleo_f446ze/nucleo_f446ze.dts:107 */
			current-speed = < 0x1c200 >;                   /* in zephyr/boards/st/nucleo_f446ze/nucleo_f446ze.dts:108 */
			status = "okay";                               /* in zephyr/boards/st/nucleo_f446ze/nucleo_f446ze.dts:109 */
		};

		/* node '/soc/serial@40011400' defined in zephyr/dts/arm/st/f4/stm32f4.dtsi:308 */
		usart6: arduino_serial: serial@40011400 {
			compatible = "st,stm32-usart",
			             "st,stm32-uart";                   /* in zephyr/dts/arm/st/f4/stm32f4.dtsi:309 */
			reg = < 0x40011400 0x400 >;                     /* in zephyr/dts/arm/st/f4/stm32f4.dtsi:310 */
			clocks = < &rcc 0x44 0x20 >;                    /* in zephyr/dts/arm/st/f4/stm32f4.dtsi:311 */
			resets = < &rctl 0x485 >;                       /* in zephyr/dts/arm/st/f4/stm32f4.dtsi:312 */
			interrupts = < 0x47 0x0 >;                      /* in zephyr/dts/arm/st/f4/stm32f4.dtsi:313 */
			pinctrl-0 = < &usart6_tx_pg14 &usart6_rx_pg9 >; /* in zephyr/boards/st/nucleo_f446ze/nucleo_f446ze.dts:120 */
			pinctrl-names = "default";                      /* in zephyr/boards/st/nucleo_f446ze/nucleo_f446ze.dts:121 */
			current-speed = < 0x1c200 >;                    /* in zephyr/boards/st/nucleo_f446ze/nucleo_f446ze.dts:122 */
			status = "okay";                                /* in zephyr/boards/st/nucleo_f446ze/nucleo_f446ze.dts:123 */
		};

		/* node '/soc/i2c@40005400' defined in zephyr/dts/arm/st/f4/stm32f4.dtsi:317 */
		i2c1: arduino_i2c: i2c@40005400 {
			compatible = "st,stm32-i2c-v1";              /* in zephyr/dts/arm/st/f4/stm32f4.dtsi:318 */
			#address-cells = < 0x1 >;                    /* in zephyr/dts/arm/st/f4/stm32f4.dtsi:320 */
			#size-cells = < 0x0 >;                       /* in zephyr/dts/arm/st/f4/stm32f4.dtsi:321 */
			reg = < 0x40005400 0x400 >;                  /* in zephyr/dts/arm/st/f4/stm32f4.dtsi:322 */
			clocks = < &rcc 0x40 0x200000 >;             /* in zephyr/dts/arm/st/f4/stm32f4.dtsi:323 */
			interrupts = < 0x1f 0x0 >,
			             < 0x20 0x0 >;                   /* in zephyr/dts/arm/st/f4/stm32f4.dtsi:324 */
			interrupt-names = "event",
			                  "error";                   /* in zephyr/dts/arm/st/f4/stm32f4.dtsi:325 */
			pinctrl-0 = < &i2c1_scl_pb8 &i2c1_sda_pb9 >; /* in zephyr/boards/st/nucleo_f446ze/nucleo_f446ze.dts:127 */
			pinctrl-names = "default";                   /* in zephyr/boards/st/nucleo_f446ze/nucleo_f446ze.dts:128 */
			status = "okay";                             /* in zephyr/boards/st/nucleo_f446ze/nucleo_f446ze.dts:129 */
			clock-frequency = < 0x61a80 >;               /* in zephyr/boards/st/nucleo_f446ze/nucleo_f446ze.dts:130 */
			phandle = < 0x2a >;                          /* in zephyr/dts/arm/st/f4/stm32f4.dtsi:707 */
		};

		/* node '/soc/i2c@40005800' defined in zephyr/dts/arm/st/f4/stm32f4.dtsi:329 */
		i2c2: i2c@40005800 {
			compatible = "st,stm32-i2c-v1";              /* in zephyr/dts/arm/st/f4/stm32f4.dtsi:330 */
			#address-cells = < 0x1 >;                    /* in zephyr/dts/arm/st/f4/stm32f4.dtsi:332 */
			#size-cells = < 0x0 >;                       /* in zephyr/dts/arm/st/f4/stm32f4.dtsi:333 */
			reg = < 0x40005800 0x400 >;                  /* in zephyr/dts/arm/st/f4/stm32f4.dtsi:334 */
			clocks = < &rcc 0x40 0x400000 >;             /* in zephyr/dts/arm/st/f4/stm32f4.dtsi:335 */
			interrupts = < 0x21 0x0 >,
			             < 0x22 0x0 >;                   /* in zephyr/dts/arm/st/f4/stm32f4.dtsi:336 */
			interrupt-names = "event",
			                  "error";                   /* in zephyr/dts/arm/st/f4/stm32f4.dtsi:337 */
			pinctrl-0 = < &i2c2_scl_pf1 &i2c2_sda_pf0 >; /* in zephyr/boards/st/nucleo_f446ze/nucleo_f446ze.dts:134 */
			pinctrl-names = "default";                   /* in zephyr/boards/st/nucleo_f446ze/nucleo_f446ze.dts:135 */
			status = "okay";                             /* in zephyr/boards/st/nucleo_f446ze/nucleo_f446ze.dts:136 */
			clock-frequency = < 0x61a80 >;               /* in zephyr/boards/st/nucleo_f446ze/nucleo_f446ze.dts:137 */
			phandle = < 0x2b >;                          /* in zephyr/dts/arm/st/f4/stm32f4.dtsi:715 */
		};

		/* node '/soc/i2c@40005c00' defined in zephyr/dts/arm/st/f4/stm32f4.dtsi:341 */
		i2c3: i2c@40005c00 {
			compatible = "st,stm32-i2c-v1";  /* in zephyr/dts/arm/st/f4/stm32f4.dtsi:342 */
			clock-frequency = < 0x186a0 >;   /* in zephyr/dts/arm/st/f4/stm32f4.dtsi:343 */
			#address-cells = < 0x1 >;        /* in zephyr/dts/arm/st/f4/stm32f4.dtsi:344 */
			#size-cells = < 0x0 >;           /* in zephyr/dts/arm/st/f4/stm32f4.dtsi:345 */
			reg = < 0x40005c00 0x400 >;      /* in zephyr/dts/arm/st/f4/stm32f4.dtsi:346 */
			clocks = < &rcc 0x40 0x800000 >; /* in zephyr/dts/arm/st/f4/stm32f4.dtsi:347 */
			interrupts = < 0x48 0x0 >,
			             < 0x49 0x0 >;       /* in zephyr/dts/arm/st/f4/stm32f4.dtsi:348 */
			interrupt-names = "event",
			                  "error";       /* in zephyr/dts/arm/st/f4/stm32f4.dtsi:349 */
			status = "disabled";             /* in zephyr/dts/arm/st/f4/stm32f4.dtsi:350 */
			phandle = < 0x2c >;              /* in zephyr/dts/arm/st/f4/stm32f4.dtsi:723 */
		};

		/* node '/soc/spi@40013000' defined in zephyr/dts/arm/st/f4/stm32f4.dtsi:353 */
		spi1: arduino_spi: spi@40013000 {
			compatible = "st,stm32-spi";                                 /* in zephyr/dts/arm/st/f4/stm32f4.dtsi:354 */
			#address-cells = < 0x1 >;                                    /* in zephyr/dts/arm/st/f4/stm32f4.dtsi:355 */
			#size-cells = < 0x0 >;                                       /* in zephyr/dts/arm/st/f4/stm32f4.dtsi:356 */
			reg = < 0x40013000 0x400 >;                                  /* in zephyr/dts/arm/st/f4/stm32f4.dtsi:357 */
			clocks = < &rcc 0x44 0x1000 >;                               /* in zephyr/dts/arm/st/f4/stm32f4.dtsi:358 */
			interrupts = < 0x23 0x0 >;                                   /* in zephyr/dts/arm/st/f4/stm32f4.dtsi:359 */
			st,spi-data-width = "limited-8-16-bit";                      /* in zephyr/dts/arm/st/f4/stm32f4.dtsi:360 */
			pinctrl-0 = < &spi1_sck_pa5 &spi1_miso_pa6 &spi1_mosi_pa7 >; /* in zephyr/boards/st/nucleo_f446ze/nucleo_f446ze.dts:141 */
			pinctrl-names = "default";                                   /* in zephyr/boards/st/nucleo_f446ze/nucleo_f446ze.dts:142 */
			cs-gpios = < &gpiod 0xe 0x11 >;                              /* in zephyr/boards/st/nucleo_f446ze/nucleo_f446ze.dts:143 */
			status = "okay";                                             /* in zephyr/boards/st/nucleo_f446ze/nucleo_f446ze.dts:144 */
		};

		/* node '/soc/usb@50000000' defined in zephyr/dts/arm/st/f4/stm32f4.dtsi:364 */
		usbotg_fs: zephyr_udc0: usb@50000000 {
			compatible = "st,stm32-otgfs";                                               /* in zephyr/dts/arm/st/f4/stm32f4.dtsi:365 */
			reg = < 0x50000000 0x40000 >;                                                /* in zephyr/dts/arm/st/f4/stm32f4.dtsi:366 */
			interrupts = < 0x43 0x0 >;                                                   /* in zephyr/dts/arm/st/f4/stm32f4.dtsi:367 */
			interrupt-names = "otgfs";                                                   /* in zephyr/dts/arm/st/f4/stm32f4.dtsi:368 */
			ram-size = < 0x500 >;                                                        /* in zephyr/dts/arm/st/f4/stm32f4.dtsi:370 */
			maximum-speed = "full-speed";                                                /* in zephyr/dts/arm/st/f4/stm32f4.dtsi:371 */
			phys = < &otgfs_phy >;                                                       /* in zephyr/dts/arm/st/f4/stm32f4.dtsi:372 */
			num-bidir-endpoints = < 0x6 >;                                               /* in zephyr/dts/arm/st/f4/stm32f446.dtsi:92 */
			clocks = < &rcc 0x34 0x80 >,
			         < &rcc 0x7 0x1b0094 >;                                              /* in zephyr/dts/arm/st/f4/stm32f446.dtsi:93 */
			pinctrl-0 = < &usb_otg_fs_dm_pa11 &usb_otg_fs_dp_pa12 &usb_otg_fs_id_pa10 >; /* in zephyr/boards/st/nucleo_f446ze/nucleo_f446ze.dts:155 */
			pinctrl-names = "default";                                                   /* in zephyr/boards/st/nucleo_f446ze/nucleo_f446ze.dts:157 */
			status = "okay";                                                             /* in zephyr/boards/st/nucleo_f446ze/nucleo_f446ze.dts:158 */
		};

		/* node '/soc/timers@40010000' defined in zephyr/dts/arm/st/f4/stm32f4.dtsi:378 */
		timers1: timers@40010000 {
			compatible = "st,stm32-timers"; /* in zephyr/dts/arm/st/f4/stm32f4.dtsi:379 */
			reg = < 0x40010000 0x400 >;     /* in zephyr/dts/arm/st/f4/stm32f4.dtsi:380 */
			clocks = < &rcc 0x44 0x1 >,
			         < &rcc 0x16 0xff >;    /* in zephyr/dts/arm/st/f4/stm32f4.dtsi:381 */
			resets = < &rctl 0x480 >;       /* in zephyr/dts/arm/st/f4/stm32f4.dtsi:383 */
			interrupts = < 0x18 0x0 >,
			             < 0x19 0x0 >,
			             < 0x1a 0x0 >,
			             < 0x1b 0x0 >;      /* in zephyr/dts/arm/st/f4/stm32f4.dtsi:384 */
			interrupt-names = "brk",
			                  "up",
			                  "trgcom",
			                  "cc";         /* in zephyr/dts/arm/st/f4/stm32f4.dtsi:385 */
			st,prescaler = < 0x0 >;         /* in zephyr/dts/arm/st/f4/stm32f4.dtsi:386 */
			status = "okay";                /* in zephyr/boards/st/nucleo_f446ze/nucleo_f446ze.dts:162 */

			/* node '/soc/timers@40010000/pwm' defined in zephyr/dts/arm/st/f4/stm32f4.dtsi:389 */
			pwm1: pwm {
				compatible = "st,stm32-pwm";   /* in zephyr/dts/arm/st/f4/stm32f4.dtsi:390 */
				#pwm-cells = < 0x3 >;          /* in zephyr/dts/arm/st/f4/stm32f4.dtsi:392 */
				status = "okay";               /* in zephyr/boards/st/nucleo_f446ze/nucleo_f446ze.dts:165 */
				pinctrl-0 = < &tim1_ch1_pe9 >; /* in zephyr/boards/st/nucleo_f446ze/nucleo_f446ze.dts:166 */
				pinctrl-names = "default";     /* in zephyr/boards/st/nucleo_f446ze/nucleo_f446ze.dts:167 */
			};

			/* node '/soc/timers@40010000/counter' defined in zephyr/dts/arm/st/f4/stm32f4.dtsi:395 */
			counter {
				compatible = "st,stm32-counter"; /* in zephyr/dts/arm/st/f4/stm32f4.dtsi:396 */
				status = "disabled";             /* in zephyr/dts/arm/st/f4/stm32f4.dtsi:397 */
			};

			/* node '/soc/timers@40010000/qdec' defined in zephyr/dts/arm/st/f4/stm32f4.dtsi:400 */
			qdec {
				compatible = "st,stm32-qdec";    /* in zephyr/dts/arm/st/f4/stm32f4.dtsi:401 */
				st,input-filter-level = < 0x0 >; /* in zephyr/dts/arm/st/f4/stm32f4.dtsi:402 */
				status = "disabled";             /* in zephyr/dts/arm/st/f4/stm32f4.dtsi:403 */
			};
		};

		/* node '/soc/timers@40000000' defined in zephyr/dts/arm/st/f4/stm32f4.dtsi:407 */
		timers2: timers@40000000 {
			compatible = "st,stm32-timers"; /* in zephyr/dts/arm/st/f4/stm32f4.dtsi:408 */
			reg = < 0x40000000 0x400 >;     /* in zephyr/dts/arm/st/f4/stm32f4.dtsi:409 */
			clocks = < &rcc 0x40 0x1 >,
			         < &rcc 0x15 0xff >;    /* in zephyr/dts/arm/st/f4/stm32f4.dtsi:410 */
			resets = < &rctl 0x400 >;       /* in zephyr/dts/arm/st/f4/stm32f4.dtsi:412 */
			interrupts = < 0x1c 0x0 >;      /* in zephyr/dts/arm/st/f4/stm32f4.dtsi:413 */
			interrupt-names = "global";     /* in zephyr/dts/arm/st/f4/stm32f4.dtsi:414 */
			st,prescaler = < 0x0 >;         /* in zephyr/dts/arm/st/f4/stm32f4.dtsi:415 */
			status = "disabled";            /* in zephyr/dts/arm/st/f4/stm32f4.dtsi:416 */

			/* node '/soc/timers@40000000/pwm' defined in zephyr/dts/arm/st/f4/stm32f4.dtsi:418 */
			pwm {
				compatible = "st,stm32-pwm"; /* in zephyr/dts/arm/st/f4/stm32f4.dtsi:419 */
				status = "disabled";         /* in zephyr/dts/arm/st/f4/stm32f4.dtsi:420 */
				#pwm-cells = < 0x3 >;        /* in zephyr/dts/arm/st/f4/stm32f4.dtsi:421 */
			};

			/* node '/soc/timers@40000000/counter' defined in zephyr/dts/arm/st/f4/stm32f4.dtsi:424 */
			counter {
				compatible = "st,stm32-counter"; /* in zephyr/dts/arm/st/f4/stm32f4.dtsi:425 */
				status = "disabled";             /* in zephyr/dts/arm/st/f4/stm32f4.dtsi:426 */
			};

			/* node '/soc/timers@40000000/qdec' defined in zephyr/dts/arm/st/f4/stm32f4.dtsi:429 */
			qdec {
				compatible = "st,stm32-qdec";    /* in zephyr/dts/arm/st/f4/stm32f4.dtsi:430 */
				st,input-filter-level = < 0x0 >; /* in zephyr/dts/arm/st/f4/stm32f4.dtsi:431 */
				status = "disabled";             /* in zephyr/dts/arm/st/f4/stm32f4.dtsi:432 */
			};
		};

		/* node '/soc/timers@40000400' defined in zephyr/dts/arm/st/f4/stm32f4.dtsi:436 */
		timers3: timers@40000400 {
			compatible = "st,stm32-timers"; /* in zephyr/dts/arm/st/f4/stm32f4.dtsi:437 */
			reg = < 0x40000400 0x400 >;     /* in zephyr/dts/arm/st/f4/stm32f4.dtsi:438 */
			clocks = < &rcc 0x40 0x2 >,
			         < &rcc 0x15 0xff >;    /* in zephyr/dts/arm/st/f4/stm32f4.dtsi:439 */
			resets = < &rctl 0x401 >;       /* in zephyr/dts/arm/st/f4/stm32f4.dtsi:441 */
			interrupts = < 0x1d 0x0 >;      /* in zephyr/dts/arm/st/f4/stm32f4.dtsi:442 */
			interrupt-names = "global";     /* in zephyr/dts/arm/st/f4/stm32f4.dtsi:443 */
			st,prescaler = < 0x0 >;         /* in zephyr/dts/arm/st/f4/stm32f4.dtsi:444 */
			status = "disabled";            /* in zephyr/dts/arm/st/f4/stm32f4.dtsi:445 */

			/* node '/soc/timers@40000400/pwm' defined in zephyr/dts/arm/st/f4/stm32f4.dtsi:447 */
			pwm {
				compatible = "st,stm32-pwm"; /* in zephyr/dts/arm/st/f4/stm32f4.dtsi:448 */
				status = "disabled";         /* in zephyr/dts/arm/st/f4/stm32f4.dtsi:449 */
				#pwm-cells = < 0x3 >;        /* in zephyr/dts/arm/st/f4/stm32f4.dtsi:450 */
			};

			/* node '/soc/timers@40000400/counter' defined in zephyr/dts/arm/st/f4/stm32f4.dtsi:453 */
			counter {
				compatible = "st,stm32-counter"; /* in zephyr/dts/arm/st/f4/stm32f4.dtsi:454 */
				status = "disabled";             /* in zephyr/dts/arm/st/f4/stm32f4.dtsi:455 */
			};

			/* node '/soc/timers@40000400/qdec' defined in zephyr/dts/arm/st/f4/stm32f4.dtsi:458 */
			qdec {
				compatible = "st,stm32-qdec";    /* in zephyr/dts/arm/st/f4/stm32f4.dtsi:459 */
				st,input-filter-level = < 0x0 >; /* in zephyr/dts/arm/st/f4/stm32f4.dtsi:460 */
				status = "disabled";             /* in zephyr/dts/arm/st/f4/stm32f4.dtsi:461 */
			};
		};

		/* node '/soc/timers@40000800' defined in zephyr/dts/arm/st/f4/stm32f4.dtsi:465 */
		timers4: timers@40000800 {
			compatible = "st,stm32-timers"; /* in zephyr/dts/arm/st/f4/stm32f4.dtsi:466 */
			reg = < 0x40000800 0x400 >;     /* in zephyr/dts/arm/st/f4/stm32f4.dtsi:467 */
			clocks = < &rcc 0x40 0x4 >,
			         < &rcc 0x15 0xff >;    /* in zephyr/dts/arm/st/f4/stm32f4.dtsi:468 */
			resets = < &rctl 0x402 >;       /* in zephyr/dts/arm/st/f4/stm32f4.dtsi:470 */
			interrupts = < 0x1e 0x0 >;      /* in zephyr/dts/arm/st/f4/stm32f4.dtsi:471 */
			interrupt-names = "global";     /* in zephyr/dts/arm/st/f4/stm32f4.dtsi:472 */
			st,prescaler = < 0x0 >;         /* in zephyr/dts/arm/st/f4/stm32f4.dtsi:473 */
			status = "disabled";            /* in zephyr/dts/arm/st/f4/stm32f4.dtsi:474 */

			/* node '/soc/timers@40000800/pwm' defined in zephyr/dts/arm/st/f4/stm32f4.dtsi:476 */
			pwm {
				compatible = "st,stm32-pwm"; /* in zephyr/dts/arm/st/f4/stm32f4.dtsi:477 */
				status = "disabled";         /* in zephyr/dts/arm/st/f4/stm32f4.dtsi:478 */
				#pwm-cells = < 0x3 >;        /* in zephyr/dts/arm/st/f4/stm32f4.dtsi:479 */
			};

			/* node '/soc/timers@40000800/counter' defined in zephyr/dts/arm/st/f4/stm32f4.dtsi:482 */
			counter {
				compatible = "st,stm32-counter"; /* in zephyr/dts/arm/st/f4/stm32f4.dtsi:483 */
				status = "disabled";             /* in zephyr/dts/arm/st/f4/stm32f4.dtsi:484 */
			};

			/* node '/soc/timers@40000800/qdec' defined in zephyr/dts/arm/st/f4/stm32f4.dtsi:487 */
			qdec {
				compatible = "st,stm32-qdec";    /* in zephyr/dts/arm/st/f4/stm32f4.dtsi:488 */
				st,input-filter-level = < 0x0 >; /* in zephyr/dts/arm/st/f4/stm32f4.dtsi:489 */
				status = "disabled";             /* in zephyr/dts/arm/st/f4/stm32f4.dtsi:490 */
			};
		};

		/* node '/soc/timers@40000c00' defined in zephyr/dts/arm/st/f4/stm32f4.dtsi:494 */
		timers5: timers@40000c00 {
			compatible = "st,stm32-timers"; /* in zephyr/dts/arm/st/f4/stm32f4.dtsi:495 */
			reg = < 0x40000c00 0x400 >;     /* in zephyr/dts/arm/st/f4/stm32f4.dtsi:496 */
			clocks = < &rcc 0x40 0x8 >,
			         < &rcc 0x15 0xff >;    /* in zephyr/dts/arm/st/f4/stm32f4.dtsi:497 */
			resets = < &rctl 0x403 >;       /* in zephyr/dts/arm/st/f4/stm32f4.dtsi:499 */
			interrupts = < 0x32 0x0 >;      /* in zephyr/dts/arm/st/f4/stm32f4.dtsi:500 */
			interrupt-names = "global";     /* in zephyr/dts/arm/st/f4/stm32f4.dtsi:501 */
			st,prescaler = < 0x0 >;         /* in zephyr/dts/arm/st/f4/stm32f4.dtsi:502 */
			status = "disabled";            /* in zephyr/dts/arm/st/f4/stm32f4.dtsi:503 */

			/* node '/soc/timers@40000c00/pwm' defined in zephyr/dts/arm/st/f4/stm32f4.dtsi:505 */
			pwm {
				compatible = "st,stm32-pwm"; /* in zephyr/dts/arm/st/f4/stm32f4.dtsi:506 */
				status = "disabled";         /* in zephyr/dts/arm/st/f4/stm32f4.dtsi:507 */
				#pwm-cells = < 0x3 >;        /* in zephyr/dts/arm/st/f4/stm32f4.dtsi:508 */
			};

			/* node '/soc/timers@40000c00/counter' defined in zephyr/dts/arm/st/f4/stm32f4.dtsi:511 */
			counter {
				compatible = "st,stm32-counter"; /* in zephyr/dts/arm/st/f4/stm32f4.dtsi:512 */
				status = "disabled";             /* in zephyr/dts/arm/st/f4/stm32f4.dtsi:513 */
			};

			/* node '/soc/timers@40000c00/qdec' defined in zephyr/dts/arm/st/f4/stm32f4.dtsi:516 */
			qdec {
				compatible = "st,stm32-qdec";    /* in zephyr/dts/arm/st/f4/stm32f4.dtsi:517 */
				st,input-filter-level = < 0x0 >; /* in zephyr/dts/arm/st/f4/stm32f4.dtsi:518 */
				status = "disabled";             /* in zephyr/dts/arm/st/f4/stm32f4.dtsi:519 */
			};
		};

		/* node '/soc/timers@40014000' defined in zephyr/dts/arm/st/f4/stm32f4.dtsi:523 */
		timers9: timers@40014000 {
			compatible = "st,stm32-timers"; /* in zephyr/dts/arm/st/f4/stm32f4.dtsi:524 */
			reg = < 0x40014000 0x400 >;     /* in zephyr/dts/arm/st/f4/stm32f4.dtsi:525 */
			clocks = < &rcc 0x44 0x10000 >,
			         < &rcc 0x16 0xff >;    /* in zephyr/dts/arm/st/f4/stm32f4.dtsi:526 */
			resets = < &rctl 0x490 >;       /* in zephyr/dts/arm/st/f4/stm32f4.dtsi:528 */
			interrupts = < 0x18 0x0 >;      /* in zephyr/dts/arm/st/f4/stm32f4.dtsi:529 */
			interrupt-names = "global";     /* in zephyr/dts/arm/st/f4/stm32f4.dtsi:530 */
			st,prescaler = < 0x0 >;         /* in zephyr/dts/arm/st/f4/stm32f4.dtsi:531 */
			status = "disabled";            /* in zephyr/dts/arm/st/f4/stm32f4.dtsi:532 */

			/* node '/soc/timers@40014000/pwm' defined in zephyr/dts/arm/st/f4/stm32f4.dtsi:534 */
			pwm {
				compatible = "st,stm32-pwm"; /* in zephyr/dts/arm/st/f4/stm32f4.dtsi:535 */
				status = "disabled";         /* in zephyr/dts/arm/st/f4/stm32f4.dtsi:536 */
				#pwm-cells = < 0x3 >;        /* in zephyr/dts/arm/st/f4/stm32f4.dtsi:537 */
			};

			/* node '/soc/timers@40014000/counter' defined in zephyr/dts/arm/st/f4/stm32f4.dtsi:540 */
			counter {
				compatible = "st,stm32-counter"; /* in zephyr/dts/arm/st/f4/stm32f4.dtsi:541 */
				status = "disabled";             /* in zephyr/dts/arm/st/f4/stm32f4.dtsi:542 */
			};
		};

		/* node '/soc/timers@40014400' defined in zephyr/dts/arm/st/f4/stm32f4.dtsi:546 */
		timers10: timers@40014400 {
			compatible = "st,stm32-timers"; /* in zephyr/dts/arm/st/f4/stm32f4.dtsi:547 */
			reg = < 0x40014400 0x400 >;     /* in zephyr/dts/arm/st/f4/stm32f4.dtsi:548 */
			clocks = < &rcc 0x44 0x20000 >,
			         < &rcc 0x16 0xff >;    /* in zephyr/dts/arm/st/f4/stm32f4.dtsi:549 */
			resets = < &rctl 0x491 >;       /* in zephyr/dts/arm/st/f4/stm32f4.dtsi:551 */
			interrupts = < 0x19 0x0 >;      /* in zephyr/dts/arm/st/f4/stm32f4.dtsi:552 */
			interrupt-names = "global";     /* in zephyr/dts/arm/st/f4/stm32f4.dtsi:553 */
			st,prescaler = < 0x0 >;         /* in zephyr/dts/arm/st/f4/stm32f4.dtsi:554 */
			status = "disabled";            /* in zephyr/dts/arm/st/f4/stm32f4.dtsi:555 */

			/* node '/soc/timers@40014400/pwm' defined in zephyr/dts/arm/st/f4/stm32f4.dtsi:557 */
			pwm {
				compatible = "st,stm32-pwm"; /* in zephyr/dts/arm/st/f4/stm32f4.dtsi:558 */
				status = "disabled";         /* in zephyr/dts/arm/st/f4/stm32f4.dtsi:559 */
				#pwm-cells = < 0x3 >;        /* in zephyr/dts/arm/st/f4/stm32f4.dtsi:560 */
			};

			/* node '/soc/timers@40014400/counter' defined in zephyr/dts/arm/st/f4/stm32f4.dtsi:563 */
			counter {
				compatible = "st,stm32-counter"; /* in zephyr/dts/arm/st/f4/stm32f4.dtsi:564 */
				status = "disabled";             /* in zephyr/dts/arm/st/f4/stm32f4.dtsi:565 */
			};
		};

		/* node '/soc/timers@40014800' defined in zephyr/dts/arm/st/f4/stm32f4.dtsi:569 */
		timers11: timers@40014800 {
			compatible = "st,stm32-timers"; /* in zephyr/dts/arm/st/f4/stm32f4.dtsi:570 */
			reg = < 0x40014800 0x400 >;     /* in zephyr/dts/arm/st/f4/stm32f4.dtsi:571 */
			clocks = < &rcc 0x44 0x40000 >,
			         < &rcc 0x16 0xff >;    /* in zephyr/dts/arm/st/f4/stm32f4.dtsi:572 */
			resets = < &rctl 0x492 >;       /* in zephyr/dts/arm/st/f4/stm32f4.dtsi:574 */
			interrupts = < 0x1a 0x0 >;      /* in zephyr/dts/arm/st/f4/stm32f4.dtsi:575 */
			interrupt-names = "global";     /* in zephyr/dts/arm/st/f4/stm32f4.dtsi:576 */
			st,prescaler = < 0x0 >;         /* in zephyr/dts/arm/st/f4/stm32f4.dtsi:577 */
			status = "disabled";            /* in zephyr/dts/arm/st/f4/stm32f4.dtsi:578 */

			/* node '/soc/timers@40014800/pwm' defined in zephyr/dts/arm/st/f4/stm32f4.dtsi:580 */
			pwm {
				compatible = "st,stm32-pwm"; /* in zephyr/dts/arm/st/f4/stm32f4.dtsi:581 */
				status = "disabled";         /* in zephyr/dts/arm/st/f4/stm32f4.dtsi:582 */
				#pwm-cells = < 0x3 >;        /* in zephyr/dts/arm/st/f4/stm32f4.dtsi:583 */
			};

			/* node '/soc/timers@40014800/counter' defined in zephyr/dts/arm/st/f4/stm32f4.dtsi:586 */
			counter {
				compatible = "st,stm32-counter"; /* in zephyr/dts/arm/st/f4/stm32f4.dtsi:587 */
				status = "disabled";             /* in zephyr/dts/arm/st/f4/stm32f4.dtsi:588 */
			};
		};

		/* node '/soc/rtc@40002800' defined in zephyr/dts/arm/st/f4/stm32f4.dtsi:592 */
		rtc: rtc@40002800 {
			compatible = "st,stm32-rtc";       /* in zephyr/dts/arm/st/f4/stm32f4.dtsi:593 */
			reg = < 0x40002800 0x400 >;        /* in zephyr/dts/arm/st/f4/stm32f4.dtsi:594 */
			interrupts = < 0x29 0x0 >;         /* in zephyr/dts/arm/st/f4/stm32f4.dtsi:595 */
			prescaler = < 0x8000 >;            /* in zephyr/dts/arm/st/f4/stm32f4.dtsi:597 */
			alarms-count = < 0x2 >;            /* in zephyr/dts/arm/st/f4/stm32f4.dtsi:598 */
			alrm-exti-line = < 0x11 >;         /* in zephyr/dts/arm/st/f4/stm32f4.dtsi:599 */
			clocks = < &rcc 0x40 0x10000000 >,
			         < &rcc 0x3 0x2280070 >;   /* in zephyr/boards/st/nucleo_f446ze/nucleo_f446ze.dts:172 */
			status = "okay";                   /* in zephyr/boards/st/nucleo_f446ze/nucleo_f446ze.dts:174 */

			/* node '/soc/rtc@40002800/backup_regs' defined in zephyr/dts/arm/st/f4/stm32f4.dtsi:602 */
			bbram: backup_regs {
				compatible = "st,stm32-bbram"; /* in zephyr/dts/arm/st/f4/stm32f4.dtsi:603 */
				st,backup-regs = < 0x14 >;     /* in zephyr/dts/arm/st/f4/stm32f4.dtsi:604 */
				status = "disabled";           /* in zephyr/dts/arm/st/f4/stm32f4.dtsi:605 */
			};
		};

		/* node '/soc/adc@40012000' defined in zephyr/dts/arm/st/f4/stm32f4.dtsi:609 */
		adc1: adc@40012000 {
			compatible = "st,stm32f4-adc",
			             "st,stm32-adc";                                 /* in zephyr/dts/arm/st/f4/stm32f4.dtsi:610 */
			reg = < 0x40012000 0x400 >;                                  /* in zephyr/dts/arm/st/f4/stm32f4.dtsi:611 */
			clocks = < &rcc 0x44 0x100 >;                                /* in zephyr/dts/arm/st/f4/stm32f4.dtsi:612 */
			clock-names = "adcx";                                        /* in zephyr/dts/arm/st/f4/stm32f4.dtsi:613 */
			interrupts = < 0x12 0x0 >;                                   /* in zephyr/dts/arm/st/f4/stm32f4.dtsi:614 */
			#io-channel-cells = < 0x1 >;                                 /* in zephyr/dts/arm/st/f4/stm32f4.dtsi:615 */
			st,adc-resolutions = < 0xc 0xa 0x8 0x6 >;                    /* in zephyr/dts/arm/st/f4/stm32f4.dtsi:616 */
			sampling-times = < 0x3 0xf 0x1c 0x38 0x54 0x70 0x90 0x1e0 >; /* in zephyr/dts/arm/st/f4/stm32f4.dtsi:617 */
			st,adc-sequencer = "programmable";                           /* in zephyr/dts/arm/st/f4/stm32f4.dtsi:619 */
			st,adc-oversampler = "none";                                 /* in zephyr/dts/arm/st/f4/stm32f4.dtsi:620 */
			st,adc-internal-regulator = "none";                          /* in zephyr/dts/arm/st/f4/stm32f4.dtsi:621 */
			st,adc-has-injected-support;                                 /* in zephyr/dts/arm/st/f4/stm32f4.dtsi:622 */
			pinctrl-0 = < &adc1_in0_pa0 >;                               /* in zephyr/boards/st/nucleo_f446ze/nucleo_f446ze.dts:92 */
			pinctrl-names = "default";                                   /* in zephyr/boards/st/nucleo_f446ze/nucleo_f446ze.dts:93 */
			st,adc-clock-source = "SYNC";                                /* in zephyr/boards/st/nucleo_f446ze/nucleo_f446ze.dts:94 */
			st,adc-prescaler = < 0x2 >;                                  /* in zephyr/boards/st/nucleo_f446ze/nucleo_f446ze.dts:95 */
			status = "okay";                                             /* in zephyr/boards/st/nucleo_f446ze/nucleo_f446ze.dts:96 */
			phandle = < 0x28 >;                                          /* in zephyr/dts/arm/st/f4/stm32f446.dtsi:198 */
		};

		/* node '/soc/dma@40026000' defined in zephyr/dts/arm/st/f4/stm32f4.dtsi:626 */
		dma1: dma@40026000 {
			compatible = "st,stm32-dma-v1";                                                      /* in zephyr/dts/arm/st/f4/stm32f4.dtsi:627 */
			#dma-cells = < 0x4 >;                                                                /* in zephyr/dts/arm/st/f4/stm32f4.dtsi:628 */
			reg = < 0x40026000 0x400 >;                                                          /* in zephyr/dts/arm/st/f4/stm32f4.dtsi:629 */
			interrupts = < 0xb 0x0 0xc 0x0 0xd 0x0 0xe 0x0 0xf 0x0 0x10 0x0 0x11 0x0 0x2f 0x0 >; /* in zephyr/dts/arm/st/f4/stm32f4.dtsi:630 */
			clocks = < &rcc 0x30 0x200000 >;                                                     /* in zephyr/dts/arm/st/f4/stm32f4.dtsi:631 */
			status = "disabled";                                                                 /* in zephyr/dts/arm/st/f4/stm32f4.dtsi:632 */
			phandle = < 0x1b >;                                                                  /* in zephyr/dts/arm/st/f4/stm32f401.dtsi:61 */
		};

		/* node '/soc/dma@40026400' defined in zephyr/dts/arm/st/f4/stm32f4.dtsi:635 */
		dma2: dma@40026400 {
			compatible = "st,stm32-dma-v1";                                                           /* in zephyr/dts/arm/st/f4/stm32f4.dtsi:636 */
			#dma-cells = < 0x4 >;                                                                     /* in zephyr/dts/arm/st/f4/stm32f4.dtsi:637 */
			reg = < 0x40026400 0x400 >;                                                               /* in zephyr/dts/arm/st/f4/stm32f4.dtsi:638 */
			interrupts = < 0x38 0x0 0x39 0x0 0x3a 0x0 0x3b 0x0 0x3c 0x0 0x44 0x0 0x45 0x0 0x46 0x0 >; /* in zephyr/dts/arm/st/f4/stm32f4.dtsi:639 */
			clocks = < &rcc 0x30 0x400000 >;                                                          /* in zephyr/dts/arm/st/f4/stm32f4.dtsi:640 */
			st,mem2mem;                                                                               /* in zephyr/dts/arm/st/f4/stm32f4.dtsi:641 */
			status = "disabled";                                                                      /* in zephyr/dts/arm/st/f4/stm32f4.dtsi:642 */
			phandle = < 0x1c >;                                                                       /* in zephyr/dts/arm/st/f4/stm32f446.dtsi:38 */
		};

		/* node '/soc/sdmmc@40012c00' defined in zephyr/dts/arm/st/f4/stm32f4.dtsi:645 */
		sdmmc1: sdmmc@40012c00 {
			compatible = "st,stm32-sdmmc"; /* in zephyr/dts/arm/st/f4/stm32f4.dtsi:646 */
			reg = < 0x40012c00 0x400 >;    /* in zephyr/dts/arm/st/f4/stm32f4.dtsi:647 */
			clocks = < &rcc 0x44 0x800 >,
			         < &rcc 0x7 0xff >;    /* in zephyr/dts/arm/st/f4/stm32f4.dtsi:648 */
			resets = < &rctl 0x48b >;      /* in zephyr/dts/arm/st/f4/stm32f4.dtsi:650 */
			interrupts = < 0x31 0x0 >;     /* in zephyr/dts/arm/st/f4/stm32f4.dtsi:651 */
			status = "disabled";           /* in zephyr/dts/arm/st/f4/stm32f4.dtsi:652 */
		};

		/* node '/soc/spi@40003800' defined in zephyr/dts/arm/st/f4/stm32f401.dtsi:21 */
		spi2: spi@40003800 {
			compatible = "st,stm32-spi";                                                   /* in zephyr/dts/arm/st/f4/stm32f401.dtsi:22 */
			#address-cells = < 0x1 >;                                                      /* in zephyr/dts/arm/st/f4/stm32f401.dtsi:23 */
			#size-cells = < 0x0 >;                                                         /* in zephyr/dts/arm/st/f4/stm32f401.dtsi:24 */
			reg = < 0x40003800 0x400 >;                                                    /* in zephyr/dts/arm/st/f4/stm32f401.dtsi:25 */
			clocks = < &rcc 0x40 0x4000 >;                                                 /* in zephyr/dts/arm/st/f4/stm32f401.dtsi:26 */
			interrupts = < 0x24 0x0 >;                                                     /* in zephyr/dts/arm/st/f4/stm32f401.dtsi:27 */
			st,spi-data-width = "limited-8-16-bit";                                        /* in zephyr/dts/arm/st/f4/stm32f401.dtsi:28 */
			pinctrl-0 = < &spi2_nss_pb12 &spi2_sck_pb13 &spi2_miso_pb14 &spi2_mosi_pb15 >; /* in zephyr/boards/st/nucleo_f446ze/nucleo_f446ze.dts:148 */
			pinctrl-names = "default";                                                     /* in zephyr/boards/st/nucleo_f446ze/nucleo_f446ze.dts:150 */
			status = "okay";                                                               /* in zephyr/boards/st/nucleo_f446ze/nucleo_f446ze.dts:151 */
		};

		/* node '/soc/spi@40003c00' defined in zephyr/dts/arm/st/f4/stm32f401.dtsi:32 */
		spi3: spi@40003c00 {
			compatible = "st,stm32-spi";            /* in zephyr/dts/arm/st/f4/stm32f401.dtsi:33 */
			#address-cells = < 0x1 >;               /* in zephyr/dts/arm/st/f4/stm32f401.dtsi:34 */
			#size-cells = < 0x0 >;                  /* in zephyr/dts/arm/st/f4/stm32f401.dtsi:35 */
			reg = < 0x40003c00 0x400 >;             /* in zephyr/dts/arm/st/f4/stm32f401.dtsi:36 */
			clocks = < &rcc 0x40 0x8000 >;          /* in zephyr/dts/arm/st/f4/stm32f401.dtsi:37 */
			interrupts = < 0x33 0x0 >;              /* in zephyr/dts/arm/st/f4/stm32f401.dtsi:38 */
			st,spi-data-width = "limited-8-16-bit"; /* in zephyr/dts/arm/st/f4/stm32f401.dtsi:39 */
			status = "disabled";                    /* in zephyr/dts/arm/st/f4/stm32f401.dtsi:40 */
		};

		/* node '/soc/spi@40013400' defined in zephyr/dts/arm/st/f4/stm32f401.dtsi:43 */
		spi4: spi@40013400 {
			compatible = "st,stm32-spi";            /* in zephyr/dts/arm/st/f4/stm32f401.dtsi:44 */
			#address-cells = < 0x1 >;               /* in zephyr/dts/arm/st/f4/stm32f401.dtsi:45 */
			#size-cells = < 0x0 >;                  /* in zephyr/dts/arm/st/f4/stm32f401.dtsi:46 */
			reg = < 0x40013400 0x400 >;             /* in zephyr/dts/arm/st/f4/stm32f401.dtsi:47 */
			clocks = < &rcc 0x44 0x2000 >;          /* in zephyr/dts/arm/st/f4/stm32f401.dtsi:48 */
			interrupts = < 0x54 0x0 >;              /* in zephyr/dts/arm/st/f4/stm32f401.dtsi:49 */
			st,spi-data-width = "limited-8-16-bit"; /* in zephyr/dts/arm/st/f4/stm32f401.dtsi:50 */
			status = "disabled";                    /* in zephyr/dts/arm/st/f4/stm32f401.dtsi:51 */
		};

		/* node '/soc/i2s@40003800' defined in zephyr/dts/arm/st/f4/stm32f401.dtsi:54 */
		i2s2: i2s@40003800 {
			compatible = "st,stm32-i2s";        /* in zephyr/dts/arm/st/f4/stm32f401.dtsi:55 */
			#address-cells = < 0x1 >;           /* in zephyr/dts/arm/st/f4/stm32f401.dtsi:56 */
			#size-cells = < 0x0 >;              /* in zephyr/dts/arm/st/f4/stm32f401.dtsi:57 */
			reg = < 0x40003800 0x400 >;         /* in zephyr/dts/arm/st/f4/stm32f401.dtsi:58 */
			clocks = < &rcc 0x40 0x4000 >;      /* in zephyr/dts/arm/st/f4/stm32f401.dtsi:59 */
			interrupts = < 0x24 0x0 >;          /* in zephyr/dts/arm/st/f4/stm32f401.dtsi:60 */
			dmas = < &dma1 0x4 0x0 0x400 0x3 >,
			       < &dma1 0x3 0x0 0x400 0x3 >; /* in zephyr/dts/arm/st/f4/stm32f401.dtsi:61 */
			dma-names = "tx",
			            "rx";                   /* in zephyr/dts/arm/st/f4/stm32f401.dtsi:63 */
			status = "disabled";                /* in zephyr/dts/arm/st/f4/stm32f401.dtsi:64 */
		};

		/* node '/soc/i2s@40003c00' defined in zephyr/dts/arm/st/f4/stm32f401.dtsi:67 */
		i2s3: i2s@40003c00 {
			compatible = "st,stm32-i2s";        /* in zephyr/dts/arm/st/f4/stm32f401.dtsi:68 */
			#address-cells = < 0x1 >;           /* in zephyr/dts/arm/st/f4/stm32f401.dtsi:69 */
			#size-cells = < 0x0 >;              /* in zephyr/dts/arm/st/f4/stm32f401.dtsi:70 */
			reg = < 0x40003c00 0x400 >;         /* in zephyr/dts/arm/st/f4/stm32f401.dtsi:71 */
			clocks = < &rcc 0x40 0x8000 >;      /* in zephyr/dts/arm/st/f4/stm32f401.dtsi:72 */
			interrupts = < 0x33 0x0 >;          /* in zephyr/dts/arm/st/f4/stm32f401.dtsi:73 */
			dmas = < &dma1 0x5 0x0 0x400 0x3 >,
			       < &dma1 0x0 0x0 0x400 0x3 >; /* in zephyr/dts/arm/st/f4/stm32f401.dtsi:74 */
			dma-names = "tx",
			            "rx";                   /* in zephyr/dts/arm/st/f4/stm32f401.dtsi:76 */
			status = "disabled";                /* in zephyr/dts/arm/st/f4/stm32f401.dtsi:77 */
		};

		/* node '/soc/i2s@40013000' defined in zephyr/dts/arm/st/f4/stm32f446.dtsi:31 */
		i2s1: i2s@40013000 {
			compatible = "st,stm32-i2s";        /* in zephyr/dts/arm/st/f4/stm32f446.dtsi:32 */
			#address-cells = < 0x1 >;           /* in zephyr/dts/arm/st/f4/stm32f446.dtsi:33 */
			#size-cells = < 0x0 >;              /* in zephyr/dts/arm/st/f4/stm32f446.dtsi:34 */
			reg = < 0x40013000 0x400 >;         /* in zephyr/dts/arm/st/f4/stm32f446.dtsi:35 */
			clocks = < &rcc 0x44 0x1000 >;      /* in zephyr/dts/arm/st/f4/stm32f446.dtsi:36 */
			interrupts = < 0x23 0x0 >;          /* in zephyr/dts/arm/st/f4/stm32f446.dtsi:37 */
			dmas = < &dma2 0x3 0x3 0x400 0x3 >,
			       < &dma2 0x2 0x3 0x400 0x3 >; /* in zephyr/dts/arm/st/f4/stm32f446.dtsi:38 */
			dma-names = "tx",
			            "rx";                   /* in zephyr/dts/arm/st/f4/stm32f446.dtsi:40 */
			status = "disabled";                /* in zephyr/dts/arm/st/f4/stm32f446.dtsi:41 */
		};

		/* node '/soc/serial@40004800' defined in zephyr/dts/arm/st/f4/stm32f446.dtsi:44 */
		usart3: serial@40004800 {
			compatible = "st,stm32-usart",
			             "st,stm32-uart";                  /* in zephyr/dts/arm/st/f4/stm32f446.dtsi:45 */
			reg = < 0x40004800 0x400 >;                    /* in zephyr/dts/arm/st/f4/stm32f446.dtsi:46 */
			clocks = < &rcc 0x40 0x40000 >;                /* in zephyr/dts/arm/st/f4/stm32f446.dtsi:47 */
			resets = < &rctl 0x412 >;                      /* in zephyr/dts/arm/st/f4/stm32f446.dtsi:48 */
			interrupts = < 0x27 0x0 >;                     /* in zephyr/dts/arm/st/f4/stm32f446.dtsi:49 */
			pinctrl-0 = < &usart3_tx_pd8 &usart3_rx_pd9 >; /* in zephyr/boards/st/nucleo_f446ze/nucleo_f446ze.dts:113 */
			pinctrl-names = "default";                     /* in zephyr/boards/st/nucleo_f446ze/nucleo_f446ze.dts:114 */
			current-speed = < 0x1c200 >;                   /* in zephyr/boards/st/nucleo_f446ze/nucleo_f446ze.dts:115 */
			status = "okay";                               /* in zephyr/boards/st/nucleo_f446ze/nucleo_f446ze.dts:116 */
		};

		/* node '/soc/serial@40004c00' defined in zephyr/dts/arm/st/f4/stm32f446.dtsi:53 */
		uart4: serial@40004c00 {
			compatible = "st,stm32-uart";   /* in zephyr/dts/arm/st/f4/stm32f446.dtsi:54 */
			reg = < 0x40004c00 0x400 >;     /* in zephyr/dts/arm/st/f4/stm32f446.dtsi:55 */
			clocks = < &rcc 0x40 0x80000 >; /* in zephyr/dts/arm/st/f4/stm32f446.dtsi:56 */
			resets = < &rctl 0x413 >;       /* in zephyr/dts/arm/st/f4/stm32f446.dtsi:57 */
			interrupts = < 0x34 0x0 >;      /* in zephyr/dts/arm/st/f4/stm32f446.dtsi:58 */
			status = "disabled";            /* in zephyr/dts/arm/st/f4/stm32f446.dtsi:59 */
		};

		/* node '/soc/serial@40005000' defined in zephyr/dts/arm/st/f4/stm32f446.dtsi:62 */
		uart5: serial@40005000 {
			compatible = "st,stm32-uart";    /* in zephyr/dts/arm/st/f4/stm32f446.dtsi:63 */
			reg = < 0x40005000 0x400 >;      /* in zephyr/dts/arm/st/f4/stm32f446.dtsi:64 */
			clocks = < &rcc 0x40 0x100000 >; /* in zephyr/dts/arm/st/f4/stm32f446.dtsi:65 */
			resets = < &rctl 0x414 >;        /* in zephyr/dts/arm/st/f4/stm32f446.dtsi:66 */
			interrupts = < 0x35 0x0 >;       /* in zephyr/dts/arm/st/f4/stm32f446.dtsi:67 */
			status = "disabled";             /* in zephyr/dts/arm/st/f4/stm32f446.dtsi:68 */
		};

		/* node '/soc/can@40006400' defined in zephyr/dts/arm/st/f4/stm32f446.dtsi:71 */
		can1: can@40006400 {
			compatible = "st,stm32-bxcan";             /* in zephyr/dts/arm/st/f4/stm32f446.dtsi:72 */
			reg = < 0x40006400 0x400 >;                /* in zephyr/dts/arm/st/f4/stm32f446.dtsi:73 */
			interrupts = < 0x13 0x0 >,
			             < 0x14 0x0 >,
			             < 0x15 0x0 >,
			             < 0x16 0x0 >;                 /* in zephyr/dts/arm/st/f4/stm32f446.dtsi:74 */
			interrupt-names = "TX",
			                  "RX0",
			                  "RX1",
			                  "SCE";                   /* in zephyr/dts/arm/st/f4/stm32f446.dtsi:75 */
			clocks = < &rcc 0x40 0x2000000 >;          /* in zephyr/dts/arm/st/f4/stm32f446.dtsi:76 */
			pinctrl-0 = < &can1_rx_pd0 &can1_tx_pd1 >; /* in zephyr/boards/st/nucleo_f446ze/nucleo_f446ze.dts:182 */
			pinctrl-names = "default";                 /* in zephyr/boards/st/nucleo_f446ze/nucleo_f446ze.dts:183 */
			status = "okay";                           /* in zephyr/boards/st/nucleo_f446ze/nucleo_f446ze.dts:184 */
		};

		/* node '/soc/can@40006800' defined in zephyr/dts/arm/st/f4/stm32f446.dtsi:80 */
		can2: can@40006800 {
			compatible = "st,stm32-bxcan";    /* in zephyr/dts/arm/st/f4/stm32f446.dtsi:81 */
			reg = < 0x40006800 0x400 >;       /* in zephyr/dts/arm/st/f4/stm32f446.dtsi:82 */
			interrupts = < 0x3f 0x0 >,
			             < 0x40 0x0 >,
			             < 0x41 0x0 >,
			             < 0x42 0x0 >;        /* in zephyr/dts/arm/st/f4/stm32f446.dtsi:83 */
			interrupt-names = "TX",
			                  "RX0",
			                  "RX1",
			                  "SCE";          /* in zephyr/dts/arm/st/f4/stm32f446.dtsi:84 */
			clocks = < &rcc 0x40 0x6000000 >; /* in zephyr/dts/arm/st/f4/stm32f446.dtsi:86 */
			master-can-reg = < 0x40006400 >;  /* in zephyr/dts/arm/st/f4/stm32f446.dtsi:87 */
			status = "disabled";              /* in zephyr/dts/arm/st/f4/stm32f446.dtsi:88 */
		};

		/* node '/soc/usb@40040000' defined in zephyr/dts/arm/st/f4/stm32f446.dtsi:97 */
		usbotg_hs: usb@40040000 {
			compatible = "st,stm32-otghs";     /* in zephyr/dts/arm/st/f4/stm32f446.dtsi:98 */
			reg = < 0x40040000 0x40000 >;      /* in zephyr/dts/arm/st/f4/stm32f446.dtsi:99 */
			interrupts = < 0x4d 0x0 >,
			             < 0x4a 0x0 >,
			             < 0x4b 0x0 >;         /* in zephyr/dts/arm/st/f4/stm32f446.dtsi:100 */
			interrupt-names = "otghs",
			                  "ep1_out",
			                  "ep1_in";        /* in zephyr/dts/arm/st/f4/stm32f446.dtsi:101 */
			num-bidir-endpoints = < 0x9 >;     /* in zephyr/dts/arm/st/f4/stm32f446.dtsi:102 */
			ram-size = < 0x1000 >;             /* in zephyr/dts/arm/st/f4/stm32f446.dtsi:103 */
			maximum-speed = "full-speed";      /* in zephyr/dts/arm/st/f4/stm32f446.dtsi:104 */
			phys = < &otghs_fs_phy >;          /* in zephyr/dts/arm/st/f4/stm32f446.dtsi:105 */
			clocks = < &rcc 0x30 0x20000000 >,
			         < &rcc 0x7 0x1b0094 >;    /* in zephyr/dts/arm/st/f4/stm32f446.dtsi:106 */
			status = "disabled";               /* in zephyr/dts/arm/st/f4/stm32f446.dtsi:108 */
		};

		/* node '/soc/memory@40024000' defined in zephyr/dts/arm/st/f4/stm32f446.dtsi:111 */
		backup_sram: memory@40024000 {
			compatible = "zephyr,memory-region",
			             "st,stm32-backup-sram";  /* in zephyr/dts/arm/st/f4/stm32f446.dtsi:112 */
			reg = < 0x40024000 0x1000 >;          /* in zephyr/dts/arm/st/f4/stm32f446.dtsi:113 */
			clocks = < &rcc 0x30 0x40000 >;       /* in zephyr/dts/arm/st/f4/stm32f446.dtsi:114 */
			zephyr,memory-region = "BACKUP_SRAM"; /* in zephyr/dts/arm/st/f4/stm32f446.dtsi:115 */
			status = "okay";                      /* in zephyr/boards/st/nucleo_f446ze/nucleo_f446ze.dts:178 */
		};

		/* node '/soc/adc@40012100' defined in zephyr/dts/arm/st/f4/stm32f446.dtsi:119 */
		adc2: adc@40012100 {
			compatible = "st,stm32f4-adc",
			             "st,stm32-adc";                                 /* in zephyr/dts/arm/st/f4/stm32f446.dtsi:120 */
			reg = < 0x40012100 0x50 >;                                   /* in zephyr/dts/arm/st/f4/stm32f446.dtsi:121 */
			clocks = < &rcc 0x44 0x200 >;                                /* in zephyr/dts/arm/st/f4/stm32f446.dtsi:122 */
			clock-names = "adcx";                                        /* in zephyr/dts/arm/st/f4/stm32f446.dtsi:123 */
			interrupts = < 0x12 0x0 >;                                   /* in zephyr/dts/arm/st/f4/stm32f446.dtsi:124 */
			#io-channel-cells = < 0x1 >;                                 /* in zephyr/dts/arm/st/f4/stm32f446.dtsi:125 */
			st,adc-resolutions = < 0xc 0xa 0x8 0x6 >;                    /* in zephyr/dts/arm/st/f4/stm32f446.dtsi:126 */
			sampling-times = < 0x3 0xf 0x1c 0x38 0x54 0x70 0x90 0x1e0 >; /* in zephyr/dts/arm/st/f4/stm32f446.dtsi:127 */
			st,adc-clock-source = "SYNC";                                /* in zephyr/dts/arm/st/f4/stm32f446.dtsi:128 */
			st,adc-sequencer = "programmable";                           /* in zephyr/dts/arm/st/f4/stm32f446.dtsi:129 */
			st,adc-oversampler = "none";                                 /* in zephyr/dts/arm/st/f4/stm32f446.dtsi:130 */
			st,adc-internal-regulator = "none";                          /* in zephyr/dts/arm/st/f4/stm32f446.dtsi:131 */
			st,adc-has-injected-support;                                 /* in zephyr/dts/arm/st/f4/stm32f446.dtsi:132 */
			status = "disabled";                                         /* in zephyr/dts/arm/st/f4/stm32f446.dtsi:133 */
		};

		/* node '/soc/adc@40012200' defined in zephyr/dts/arm/st/f4/stm32f446.dtsi:136 */
		adc3: adc@40012200 {
			compatible = "st,stm32f4-adc",
			             "st,stm32-adc";                                 /* in zephyr/dts/arm/st/f4/stm32f446.dtsi:137 */
			reg = < 0x40012200 0x50 >;                                   /* in zephyr/dts/arm/st/f4/stm32f446.dtsi:138 */
			clocks = < &rcc 0x44 0x400 >;                                /* in zephyr/dts/arm/st/f4/stm32f446.dtsi:139 */
			clock-names = "adcx";                                        /* in zephyr/dts/arm/st/f4/stm32f446.dtsi:140 */
			interrupts = < 0x12 0x0 >;                                   /* in zephyr/dts/arm/st/f4/stm32f446.dtsi:141 */
			#io-channel-cells = < 0x1 >;                                 /* in zephyr/dts/arm/st/f4/stm32f446.dtsi:142 */
			st,adc-resolutions = < 0xc 0xa 0x8 0x6 >;                    /* in zephyr/dts/arm/st/f4/stm32f446.dtsi:143 */
			sampling-times = < 0x3 0xf 0x1c 0x38 0x54 0x70 0x90 0x1e0 >; /* in zephyr/dts/arm/st/f4/stm32f446.dtsi:144 */
			st,adc-clock-source = "SYNC";                                /* in zephyr/dts/arm/st/f4/stm32f446.dtsi:145 */
			st,adc-sequencer = "programmable";                           /* in zephyr/dts/arm/st/f4/stm32f446.dtsi:146 */
			st,adc-oversampler = "none";                                 /* in zephyr/dts/arm/st/f4/stm32f446.dtsi:147 */
			st,adc-internal-regulator = "none";                          /* in zephyr/dts/arm/st/f4/stm32f446.dtsi:148 */
			st,adc-has-injected-support;                                 /* in zephyr/dts/arm/st/f4/stm32f446.dtsi:149 */
			status = "disabled";                                         /* in zephyr/dts/arm/st/f4/stm32f446.dtsi:150 */
		};

		/* node '/soc/dac@40007400' defined in zephyr/dts/arm/st/f4/stm32f446.dtsi:153 */
		dac1: dac@40007400 {
			compatible = "st,stm32-dac";       /* in zephyr/dts/arm/st/f4/stm32f446.dtsi:154 */
			reg = < 0x40007400 0x400 >;        /* in zephyr/dts/arm/st/f4/stm32f446.dtsi:155 */
			clocks = < &rcc 0x40 0x20000000 >; /* in zephyr/dts/arm/st/f4/stm32f446.dtsi:156 */
			#io-channel-cells = < 0x1 >;       /* in zephyr/dts/arm/st/f4/stm32f446.dtsi:158 */
			status = "okay";                   /* in zephyr/boards/st/nucleo_f446ze/nucleo_f446ze.dts:100 */
			pinctrl-0 = < &dac_out1_pa4 >;     /* in zephyr/boards/st/nucleo_f446ze/nucleo_f446ze.dts:101 */
			pinctrl-names = "default";         /* in zephyr/boards/st/nucleo_f446ze/nucleo_f446ze.dts:102 */
		};

		/* node '/soc/memory-controller@a0000000' defined in zephyr/dts/arm/st/f4/stm32f446.dtsi:161 */
		fmc: memory-controller@a0000000 {
			compatible = "st,stm32-fmc"; /* in zephyr/dts/arm/st/f4/stm32f446.dtsi:162 */
			reg = < 0xa0000000 0x400 >;  /* in zephyr/dts/arm/st/f4/stm32f446.dtsi:163 */
			clocks = < &rcc 0x38 0x1 >;  /* in zephyr/dts/arm/st/f4/stm32f446.dtsi:164 */
			status = "disabled";         /* in zephyr/dts/arm/st/f4/stm32f446.dtsi:165 */

			/* node '/soc/memory-controller@a0000000/sdram' defined in zephyr/dts/arm/st/f4/stm32f446.dtsi:167 */
			sdram: sdram {
				compatible = "st,stm32-fmc-sdram"; /* in zephyr/dts/arm/st/f4/stm32f446.dtsi:168 */
				#address-cells = < 0x1 >;          /* in zephyr/dts/arm/st/f4/stm32f446.dtsi:169 */
				#size-cells = < 0x0 >;             /* in zephyr/dts/arm/st/f4/stm32f446.dtsi:170 */
				status = "disabled";               /* in zephyr/dts/arm/st/f4/stm32f446.dtsi:171 */
			};
		};

		/* node '/soc/sai1@40015800' defined in zephyr/dts/arm/st/f4/stm32f446.dtsi:175 */
		sai1: sai1@40015800 {
			compatible = "st,stm32-sai";     /* in zephyr/dts/arm/st/f4/stm32f446.dtsi:176 */
			#address-cells = < 0x1 >;        /* in zephyr/dts/arm/st/f4/stm32f446.dtsi:177 */
			#size-cells = < 0x0 >;           /* in zephyr/dts/arm/st/f4/stm32f446.dtsi:178 */
			reg = < 0x40015800 0x400 >;      /* in zephyr/dts/arm/st/f4/stm32f446.dtsi:179 */
			clocks = < &rcc 0x44 0x400000 >; /* in zephyr/dts/arm/st/f4/stm32f446.dtsi:180 */
			status = "disabled";             /* in zephyr/dts/arm/st/f4/stm32f446.dtsi:181 */

			/* node '/soc/sai1@40015800/sai1a@4' defined in zephyr/dts/arm/st/f4/stm32f446.dtsi:183 */
			sai1_a: sai1a@4 {
				reg = < 0x4 >;                        /* in zephyr/dts/arm/st/f4/stm32f446.dtsi:184 */
				dmas = < &dma2 0x1 0x0 0x22800 0x0 >; /* in zephyr/dts/arm/st/f4/stm32f446.dtsi:185 */
				status = "disabled";                  /* in zephyr/dts/arm/st/f4/stm32f446.dtsi:186 */
			};

			/* node '/soc/sai1@40015800/sai1b@24' defined in zephyr/dts/arm/st/f4/stm32f446.dtsi:189 */
			sai1_b: sai1b@24 {
				reg = < 0x24 >;                       /* in zephyr/dts/arm/st/f4/stm32f446.dtsi:190 */
				dmas = < &dma2 0x5 0x0 0x22800 0x0 >; /* in zephyr/dts/arm/st/f4/stm32f446.dtsi:191 */
				status = "disabled";                  /* in zephyr/dts/arm/st/f4/stm32f446.dtsi:192 */
			};
		};
	};

	/* node '/cpus' defined in zephyr/dts/arm/st/f4/stm32f4.dtsi:30 */
	cpus {
		#address-cells = < 0x1 >; /* in zephyr/dts/arm/st/f4/stm32f4.dtsi:31 */
		#size-cells = < 0x0 >;    /* in zephyr/dts/arm/st/f4/stm32f4.dtsi:32 */

		/* node '/cpus/cpu@0' defined in zephyr/dts/arm/st/f4/stm32f4.dtsi:34 */
		cpu0: cpu@0 {
			device_type = "cpu";           /* in zephyr/dts/arm/st/f4/stm32f4.dtsi:35 */
			compatible = "arm,cortex-m4f"; /* in zephyr/dts/arm/st/f4/stm32f4.dtsi:36 */
			reg = < 0x0 >;                 /* in zephyr/dts/arm/st/f4/stm32f4.dtsi:37 */
			cpu-power-states = < &stop >;  /* in zephyr/dts/arm/st/f4/stm32f4.dtsi:38 */
		};

		/* node '/cpus/power-states' defined in zephyr/dts/arm/st/f4/stm32f4.dtsi:41 */
		power-states {

			/* node '/cpus/power-states/stop' defined in zephyr/dts/arm/st/f4/stm32f4.dtsi:42 */
			stop: stop {
				compatible = "zephyr,power-state";    /* in zephyr/dts/arm/st/f4/stm32f4.dtsi:43 */
				power-state-name = "suspend-to-idle"; /* in zephyr/dts/arm/st/f4/stm32f4.dtsi:44 */
				min-residency-us = < 0x190 >;         /* in zephyr/dts/arm/st/f4/stm32f4.dtsi:51 */
				exit-latency-us = < 0x12c >;          /* in zephyr/dts/arm/st/f4/stm32f4.dtsi:52 */
				phandle = < 0x23 >;                   /* in zephyr/dts/arm/st/f4/stm32f4.dtsi:38 */
			};
		};
	};

	/* node '/memory@20000000' defined in zephyr/dts/arm/st/f4/stm32f4.dtsi:57 */
	sram0: memory@20000000 {
		compatible = "zephyr,memory-region",
		             "mmio-sram";            /* in zephyr/dts/arm/st/f4/stm32f4.dtsi:58 */
		zephyr,memory-region = "SRAM0";      /* in zephyr/dts/arm/st/f4/stm32f4.dtsi:59 */
		reg = < 0x20000000 0x20000 >;        /* in zephyr/dts/arm/st/f4/stm32f446Xe.dtsi:11 */
	};

	/* node '/clocks' defined in zephyr/dts/arm/st/f4/stm32f4.dtsi:62 */
	clocks {

		/* node '/clocks/clk-hse' defined in zephyr/dts/arm/st/f4/stm32f4.dtsi:63 */
		clk_hse: clk-hse {
			#clock-cells = < 0x0 >;            /* in zephyr/dts/arm/st/f4/stm32f4.dtsi:64 */
			compatible = "st,stm32-hse-clock"; /* in zephyr/dts/arm/st/f4/stm32f4.dtsi:65 */
			hse-bypass;                        /* in zephyr/boards/st/nucleo_f446ze/nucleo_f446ze.dts:69 */
			clock-frequency = < 0x7a1200 >;    /* in zephyr/boards/st/nucleo_f446ze/nucleo_f446ze.dts:70 */
			status = "okay";                   /* in zephyr/boards/st/nucleo_f446ze/nucleo_f446ze.dts:71 */
			phandle = < 0x24 >;                /* in zephyr/boards/st/nucleo_f446ze/nucleo_f446ze.dts:79 */
		};

		/* node '/clocks/clk-hsi' defined in zephyr/dts/arm/st/f4/stm32f4.dtsi:69 */
		clk_hsi: clk-hsi {
			#clock-cells = < 0x0 >;         /* in zephyr/dts/arm/st/f4/stm32f4.dtsi:70 */
			compatible = "fixed-clock";     /* in zephyr/dts/arm/st/f4/stm32f4.dtsi:71 */
			clock-frequency = < 0xf42400 >; /* in zephyr/dts/arm/st/f4/stm32f4.dtsi:72 */
			status = "disabled";            /* in zephyr/dts/arm/st/f4/stm32f4.dtsi:73 */
		};

		/* node '/clocks/clk-lse' defined in zephyr/dts/arm/st/f4/stm32f4.dtsi:76 */
		clk_lse: clk-lse {
			#clock-cells = < 0x0 >;       /* in zephyr/dts/arm/st/f4/stm32f4.dtsi:77 */
			compatible = "fixed-clock";   /* in zephyr/dts/arm/st/f4/stm32f4.dtsi:78 */
			clock-frequency = < 0x8000 >; /* in zephyr/dts/arm/st/f4/stm32f4.dtsi:79 */
			status = "disabled";          /* in zephyr/dts/arm/st/f4/stm32f4.dtsi:80 */
		};

		/* node '/clocks/clk-lsi' defined in zephyr/dts/arm/st/f4/stm32f4.dtsi:83 */
		clk_lsi: clk-lsi {
			#clock-cells = < 0x0 >;       /* in zephyr/dts/arm/st/f4/stm32f4.dtsi:84 */
			compatible = "fixed-clock";   /* in zephyr/dts/arm/st/f4/stm32f4.dtsi:85 */
			clock-frequency = < 0x7d00 >; /* in zephyr/dts/arm/st/f4/stm32f4.dtsi:86 */
			status = "okay";              /* in zephyr/boards/st/nucleo_f446ze/nucleo_f446ze.dts:65 */
		};

		/* node '/clocks/pll' defined in zephyr/dts/arm/st/f4/stm32f4.dtsi:90 */
		pll: pll {
			#clock-cells = < 0x0 >;              /* in zephyr/dts/arm/st/f4/stm32f4.dtsi:91 */
			compatible = "st,stm32fx-pll-clock"; /* in zephyr/dts/arm/st/f4/stm32f4.dtsi:92 */
			div-m = < 0x8 >;                     /* in zephyr/boards/st/nucleo_f446ze/nucleo_f446ze.dts:75 */
			mul-n = < 0x150 >;                   /* in zephyr/boards/st/nucleo_f446ze/nucleo_f446ze.dts:76 */
			div-p = < 0x2 >;                     /* in zephyr/boards/st/nucleo_f446ze/nucleo_f446ze.dts:77 */
			div-q = < 0x7 >;                     /* in zephyr/boards/st/nucleo_f446ze/nucleo_f446ze.dts:78 */
			clocks = < &clk_hse >;               /* in zephyr/boards/st/nucleo_f446ze/nucleo_f446ze.dts:79 */
			status = "okay";                     /* in zephyr/boards/st/nucleo_f446ze/nucleo_f446ze.dts:80 */
			phandle = < 0x2 >;                   /* in zephyr/boards/st/nucleo_f446ze/nucleo_f446ze.dts:84 */
		};

		/* node '/clocks/plli2s' defined in zephyr/dts/arm/st/f4/stm32f401.dtsi:11 */
		plli2s: plli2s {
			#clock-cells = < 0x0 >;              /* in zephyr/dts/arm/st/f4/stm32f401.dtsi:12 */
			compatible = "st,stm32fx-pll-clock"; /* in zephyr/dts/arm/st/f4/stm32f401.dtsi:13 */
			status = "disabled";                 /* in zephyr/dts/arm/st/f4/stm32f401.dtsi:14 */
		};

		/* node '/clocks/pllsai' defined in zephyr/dts/arm/st/f4/stm32f446.dtsi:14 */
		pllsai: pllsai {
			compatible = "st,stm32fx-pll-clock"; /* in zephyr/dts/arm/st/f4/stm32f446.dtsi:15 */
			#clock-cells = < 0x0 >;              /* in zephyr/dts/arm/st/f4/stm32f446.dtsi:16 */
			status = "disabled";                 /* in zephyr/dts/arm/st/f4/stm32f446.dtsi:17 */
		};

		/* node '/clocks/clk48' defined in zephyr/dts/arm/st/f4/stm32f446.dtsi:20 */
		clk48: clk48 {
			#clock-cells = < 0x0 >;            /* in zephyr/dts/arm/st/f4/stm32f446.dtsi:21 */
			compatible = "st,stm32-clock-mux"; /* in zephyr/dts/arm/st/f4/stm32f446.dtsi:22 */
			clocks = < &rcc 0x7 0x1b0094 >;    /* in zephyr/dts/arm/st/f4/stm32f446.dtsi:23 */
			status = "disabled";               /* in zephyr/dts/arm/st/f4/stm32f446.dtsi:24 */
		};
	};

	/* node '/mcos' defined in zephyr/dts/arm/st/f4/stm32f4.dtsi:97 */
	mcos {

		/* node '/mcos/mco1' defined in zephyr/dts/arm/st/f4/stm32f4.dtsi:98 */
		mco1: mco1 {
			compatible = "st,stm32-clock-mco"; /* in zephyr/dts/arm/st/f4/stm32f4.dtsi:99 */
			clock-names = "clksel";            /* in zephyr/dts/arm/st/f4/stm32f4.dtsi:100 */
			status = "disabled";               /* in zephyr/dts/arm/st/f4/stm32f4.dtsi:101 */
		};

		/* node '/mcos/mco2' defined in zephyr/dts/arm/st/f4/stm32f4.dtsi:104 */
		mco2: mco2 {
			compatible = "st,stm32-clock-mco"; /* in zephyr/dts/arm/st/f4/stm32f4.dtsi:105 */
			clock-names = "clksel";            /* in zephyr/dts/arm/st/f4/stm32f4.dtsi:106 */
			status = "disabled";               /* in zephyr/dts/arm/st/f4/stm32f4.dtsi:107 */
		};
	};

	/* node '/power@40007000' defined in zephyr/dts/arm/st/f4/stm32f4.dtsi:656 */
	pwr: power@40007000 {
		compatible = "st,stm32-pwr"; /* in zephyr/dts/arm/st/f4/stm32f4.dtsi:657 */
		reg = < 0x40007000 0x400 >;  /* in zephyr/dts/arm/st/f4/stm32f4.dtsi:658 */
		status = "disabled";         /* in zephyr/dts/arm/st/f4/stm32f4.dtsi:659 */
		wkup-pins-nb = < 0x1 >;      /* in zephyr/dts/arm/st/f4/stm32f4.dtsi:661 */
		#address-cells = < 0x1 >;    /* in zephyr/dts/arm/st/f4/stm32f4.dtsi:663 */
		#size-cells = < 0x0 >;       /* in zephyr/dts/arm/st/f4/stm32f4.dtsi:664 */

		/* node '/power@40007000/wkup-pin@1' defined in zephyr/dts/arm/st/f4/stm32f4.dtsi:666 */
		wkup-pin@1 {
			reg = < 0x1 >;                   /* in zephyr/dts/arm/st/f4/stm32f4.dtsi:667 */
			wkup-gpios = < &gpioa 0x0 0x1 >; /* in zephyr/dts/arm/st/f4/stm32f4.dtsi:668 */
		};
	};

	/* node '/dietemp' defined in zephyr/dts/arm/st/f4/stm32f4.dtsi:672 */
	die_temp: dietemp {
		compatible = "st,stm32-temp-cal"; /* in zephyr/dts/arm/st/f4/stm32f4.dtsi:673 */
		nvmem-cells = < &ts_cal1_otp >,
		              < &ts_cal2_otp >;   /* in zephyr/dts/arm/st/f4/stm32f4.dtsi:674 */
		nvmem-cell-names = "TS_CAL1",
		                   "TS_CAL2";     /* in zephyr/dts/arm/st/f4/stm32f4.dtsi:675 */
		ts-cal1-temp = < 0x1e >;          /* in zephyr/dts/arm/st/f4/stm32f4.dtsi:676 */
		ts-cal2-temp = < 0x6e >;          /* in zephyr/dts/arm/st/f4/stm32f4.dtsi:677 */
		ts-cal-vrefanalog = < 0xce4 >;    /* in zephyr/dts/arm/st/f4/stm32f4.dtsi:678 */
		status = "disabled";              /* in zephyr/dts/arm/st/f4/stm32f4.dtsi:680 */
		io-channels = < &adc1 0x12 >;     /* in zephyr/dts/arm/st/f4/stm32f446.dtsi:198 */
	};

	/* node '/vref' defined in zephyr/dts/arm/st/f4/stm32f4.dtsi:683 */
	vref: vref {
		compatible = "st,stm32-vref";   /* in zephyr/dts/arm/st/f4/stm32f4.dtsi:684 */
		nvmem-cells = < &vrefint_otp >; /* in zephyr/dts/arm/st/f4/stm32f4.dtsi:685 */
		vrefint-cal-mv = < 0xce4 >;     /* in zephyr/dts/arm/st/f4/stm32f4.dtsi:686 */
		io-channels = < &adc1 0x11 >;   /* in zephyr/dts/arm/st/f4/stm32f4.dtsi:687 */
		status = "okay";                /* in zephyr/boards/st/nucleo_f446ze/nucleo_f446ze.dts:232 */
	};

	/* node '/vbat' defined in zephyr/dts/arm/st/f4/stm32f4.dtsi:691 */
	vbat: vbat {
		compatible = "st,stm32-vbat"; /* in zephyr/dts/arm/st/f4/stm32f4.dtsi:692 */
		ratio = < 0x4 >;              /* in zephyr/dts/arm/st/f4/stm32f4.dtsi:693 */
		io-channels = < &adc1 0x12 >; /* in zephyr/dts/arm/st/f4/stm32f4.dtsi:694 */
		status = "okay";              /* in zephyr/boards/st/nucleo_f446ze/nucleo_f446ze.dts:236 */
	};

	/* node '/otgfs_phy' defined in zephyr/dts/arm/st/f4/stm32f4.dtsi:698 */
	otgfs_phy: otgfs_phy {
		compatible = "usb-nop-xceiv"; /* in zephyr/dts/arm/st/f4/stm32f4.dtsi:699 */
		#phy-cells = < 0x0 >;         /* in zephyr/dts/arm/st/f4/stm32f4.dtsi:700 */
		phandle = < 0x11 >;           /* in zephyr/dts/arm/st/f4/stm32f4.dtsi:372 */
	};

	/* node '/smbus1' defined in zephyr/dts/arm/st/f4/stm32f4.dtsi:703 */
	smbus1: smbus1 {
		compatible = "st,stm32-smbus"; /* in zephyr/dts/arm/st/f4/stm32f4.dtsi:704 */
		#address-cells = < 0x1 >;      /* in zephyr/dts/arm/st/f4/stm32f4.dtsi:705 */
		#size-cells = < 0x0 >;         /* in zephyr/dts/arm/st/f4/stm32f4.dtsi:706 */
		i2c = < &i2c1 >;               /* in zephyr/dts/arm/st/f4/stm32f4.dtsi:707 */
		status = "disabled";           /* in zephyr/dts/arm/st/f4/stm32f4.dtsi:708 */
	};

	/* node '/smbus2' defined in zephyr/dts/arm/st/f4/stm32f4.dtsi:711 */
	smbus2: smbus2 {
		compatible = "st,stm32-smbus"; /* in zephyr/dts/arm/st/f4/stm32f4.dtsi:712 */
		#address-cells = < 0x1 >;      /* in zephyr/dts/arm/st/f4/stm32f4.dtsi:713 */
		#size-cells = < 0x0 >;         /* in zephyr/dts/arm/st/f4/stm32f4.dtsi:714 */
		i2c = < &i2c2 >;               /* in zephyr/dts/arm/st/f4/stm32f4.dtsi:715 */
		status = "disabled";           /* in zephyr/dts/arm/st/f4/stm32f4.dtsi:716 */
	};

	/* node '/smbus3' defined in zephyr/dts/arm/st/f4/stm32f4.dtsi:719 */
	smbus3: smbus3 {
		compatible = "st,stm32-smbus"; /* in zephyr/dts/arm/st/f4/stm32f4.dtsi:720 */
		#address-cells = < 0x1 >;      /* in zephyr/dts/arm/st/f4/stm32f4.dtsi:721 */
		#size-cells = < 0x0 >;         /* in zephyr/dts/arm/st/f4/stm32f4.dtsi:722 */
		i2c = < &i2c3 >;               /* in zephyr/dts/arm/st/f4/stm32f4.dtsi:723 */
		status = "disabled";           /* in zephyr/dts/arm/st/f4/stm32f4.dtsi:724 */
	};

	/* node '/otghs_fs_phy' defined in zephyr/dts/arm/st/f4/stm32f446.dtsi:201 */
	otghs_fs_phy: otghs_fs_phy {
		compatible = "usb-nop-xceiv"; /* in zephyr/dts/arm/st/f4/stm32f446.dtsi:202 */
		#phy-cells = < 0x0 >;         /* in zephyr/dts/arm/st/f4/stm32f446.dtsi:203 */
		phandle = < 0x21 >;           /* in zephyr/dts/arm/st/f4/stm32f446.dtsi:105 */
	};

	/* node '/connector' defined in zephyr/boards/st/nucleo_f446ze/arduino_r3_connector.dtsi:10 */
	arduino_header: connector {
		compatible = "arduino-header-r3";          /* in zephyr/boards/st/nucleo_f446ze/arduino_r3_connector.dtsi:11 */
		#gpio-cells = < 0x2 >;                     /* in zephyr/boards/st/nucleo_f446ze/arduino_r3_connector.dtsi:12 */
		gpio-map-mask = < 0xffffffff 0xffffffc0 >; /* in zephyr/boards/st/nucleo_f446ze/arduino_r3_connector.dtsi:13 */
		gpio-map-pass-thru = < 0x0 0x3f >;         /* in zephyr/boards/st/nucleo_f446ze/arduino_r3_connector.dtsi:14 */
		gpio-map = < 0x0 0x0 &gpioa 0x3 0x0 >,
		           < 0x1 0x0 &gpioc 0x0 0x0 >,
		           < 0x2 0x0 &gpioc 0x3 0x0 >,
		           < 0x3 0x0 &gpiof 0x3 0x0 >,
		           < 0x4 0x0 &gpiof 0x5 0x0 >,
		           < 0x5 0x0 &gpiof 0xa 0x0 >,
		           < 0x6 0x0 &gpiog 0x9 0x0 >,
		           < 0x7 0x0 &gpiog 0xe 0x0 >,
		           < 0x8 0x0 &gpiof 0xf 0x0 >,
		           < 0x9 0x0 &gpioe 0xd 0x0 >,
		           < 0xa 0x0 &gpiof 0xe 0x0 >,
		           < 0xb 0x0 &gpioe 0xb 0x0 >,
		           < 0xc 0x0 &gpioe 0x9 0x0 >,
		           < 0xd 0x0 &gpiof 0xd 0x0 >,
		           < 0xe 0x0 &gpiof 0xc 0x0 >,
		           < 0xf 0x0 &gpiod 0xf 0x0 >,
		           < 0x10 0x0 &gpiod 0xe 0x0 >,
		           < 0x11 0x0 &gpioa 0x7 0x0 >,
		           < 0x12 0x0 &gpioa 0x6 0x0 >,
		           < 0x13 0x0 &gpioa 0x5 0x0 >,
		           < 0x14 0x0 &gpiob 0x9 0x0 >,
		           < 0x15 0x0 &gpiob 0x8 0x0 >;    /* in zephyr/boards/st/nucleo_f446ze/arduino_r3_connector.dtsi:15 */
	};

	/* node '/leds' defined in zephyr/boards/st/nucleo_f446ze/nucleo_f446ze.dts:25 */
	leds: leds {
		compatible = "gpio-leds"; /* in zephyr/boards/st/nucleo_f446ze/nucleo_f446ze.dts:26 */

		/* node '/leds/led_1' defined in zephyr/boards/st/nucleo_f446ze/nucleo_f446ze.dts:28 */
		green_led_1: led_1 {
			gpios = < &gpiob 0x0 0x0 >; /* in zephyr/boards/st/nucleo_f446ze/nucleo_f446ze.dts:29 */
			label = "User LD1";         /* in zephyr/boards/st/nucleo_f446ze/nucleo_f446ze.dts:30 */
		};

		/* node '/leds/led_2' defined in zephyr/boards/st/nucleo_f446ze/nucleo_f446ze.dts:33 */
		blue_led_2: led_2 {
			gpios = < &gpiob 0x7 0x0 >; /* in zephyr/boards/st/nucleo_f446ze/nucleo_f446ze.dts:34 */
			label = "User LD2";         /* in zephyr/boards/st/nucleo_f446ze/nucleo_f446ze.dts:35 */
		};

		/* node '/leds/led_3' defined in zephyr/boards/st/nucleo_f446ze/nucleo_f446ze.dts:38 */
		red_led_3: led_3 {
			gpios = < &gpiob 0xe 0x0 >; /* in zephyr/boards/st/nucleo_f446ze/nucleo_f446ze.dts:39 */
			label = "User LD3";         /* in zephyr/boards/st/nucleo_f446ze/nucleo_f446ze.dts:40 */
		};
	};

	/* node '/gpio_keys' defined in zephyr/boards/st/nucleo_f446ze/nucleo_f446ze.dts:44 */
	gpio_keys {
		compatible = "gpio-keys"; /* in zephyr/boards/st/nucleo_f446ze/nucleo_f446ze.dts:45 */

		/* node '/gpio_keys/button' defined in zephyr/boards/st/nucleo_f446ze/nucleo_f446ze.dts:47 */
		user_button: button {
			label = "User";             /* in zephyr/boards/st/nucleo_f446ze/nucleo_f446ze.dts:48 */
			gpios = < &gpioc 0xd 0x1 >; /* in zephyr/boards/st/nucleo_f446ze/nucleo_f446ze.dts:49 */
			zephyr,code = < 0xb >;      /* in zephyr/boards/st/nucleo_f446ze/nucleo_f446ze.dts:50 */
		};
	};
};
